[part 5 of 15: package /Cluster]
AUTOSAR XML (schema 4-3-0)
package /Cluster  (continued)
  can cluster HCP3_CANFD01: baudrate=500000, protocol-name=CAN, protocol-version=2.0, bus-off-recovery={bor-counter-l-1-to-l-2=1, bor-time-l-1=0.05, bor-time-l-2=0.2}, can-fd-baudrate=1000000  (continued)
    can physical channel CHNL: comm-connectors=CN_HCP3_CANFD01  (continued)
      frame PID_DispInpPID_Resp_FD_XIX_HCP3_CANFD01: id 0x1CD2236A, from HCP3_IONode, frame-length=64, can-addressing-mode=EXTENDED, can-frame-rx-behavior=CAN-FD, can-frame-tx-behavior=CAN-FD
        n pdu PID_DispInpPID_Resp_FD_XIX_HCP3_CANFD01: length=64
      frame PID_KeyInpPID_Req_FD_XIX_HCP3_CANFD01: id 0x1CD0236D, to HCP3_IONode, frame-length=64, can-addressing-mode=EXTENDED, can-frame-rx-behavior=CAN-FD, can-frame-tx-behavior=CAN-FD
        n pdu PID_KeyInpPID_Req_FD_XIX_HCP3_CANFD01: length=64
      frame PID_KeyInpPID_Resp_FD_XIX_HCP3_CANFD01: id 0x1CD2236D, from HCP3_IONode, frame-length=64, can-addressing-mode=EXTENDED, can-frame-rx-behavior=CAN-FD, can-frame-tx-behavior=CAN-FD
        n pdu PID_KeyInpPID_Resp_FD_XIX_HCP3_CANFD01: length=64
      frame PID_VA_Communication_Init_XIX_HCP3_CANFD01: id 0x16A95588, to HCP3_IONode, frame-length=20, can-addressing-mode=EXTENDED, can-frame-rx-behavior=CAN-FD, can-frame-tx-behavior=CAN-FD
        pdu PID_VA_Communication_Init_XIX_HCP3_CANFD01: length=20, minimum-delay=0.1, transmission-mode-true-timing={cyclic-timing={time-offset=0.0, time-period=1.0}, event-controlled-timing={number-of-repetitions=0, repetition-period=0.0}}, unused-bit-pattern=0
          signal PID_VA_Communication_Init_XIX_PID_VA_Communication_Init_XIX_HCP3_CANFD01: start 0, 136 bit, opaque, data-type-policy=OVERRIDE, i-signal-type=ARRAY, init-value=17 x 0, base-type=BT_PID_VA_Communication_Init, implementation-data-type=PID_VA_Communication_Init, transfer-property=TRIGGERED-ON-CHANGE-WITHOUT-REPETITION, to HCP3_IONode(timeout 5 s)  # This data channel is used for display video authentication of PID.
      frame PID_VA_Communication_Init_Ack_XIX_HCP3_CANFD01: id 0x16A9556A, to HCP3_IONode, frame-length=20, can-addressing-mode=EXTENDED, can-frame-rx-behavior=CAN-FD, can-frame-tx-behavior=CAN-FD
        pdu PID_VA_Communication_Init_Ack_XIX_HCP3_CANFD01: length=20, minimum-delay=0.1, transmission-mode-true-timing={cyclic-timing={time-offset=0.0, time-period=1.0}, event-controlled-timing={number-of-repetitions=0, repetition-period=0.0}}, unused-bit-pattern=0
          signal PID_VA_Communication_Init_Ack_XIX_PID_VA_Communication_Init_Ack_XIX_HCP3_CANFD01: start 0, 136 bit, opaque, data-type-policy=OVERRIDE, i-signal-type=ARRAY, init-value=17 x 0, base-type=BT_PID_VA_Communication_Init_Ack, implementation-data-type=PID_VA_Communication_Init_Ack, transfer-property=TRIGGERED-ON-CHANGE-WITHOUT-REPETITION, to HCP3_IONode(timeout 5 s)  # Init communication acknowledge of video-authentication for PID
      frame PID_VA_Response_XIX_HCP3_CANFD01: id 0x16A9556B, to HCP3_IONode, frame-length=64, can-addressing-mode=EXTENDED, can-frame-rx-behavior=CAN-FD, can-frame-tx-behavior=CAN-FD
        pdu PID_VA_Response_XIX_HCP3_CANFD01: length=64, minimum-delay=0.1, transmission-mode-true-timing={cyclic-timing={time-offset=0.0, time-period=1.0}, event-controlled-timing={number-of-repetitions=0, repetition-period=0.0}}, unused-bit-pattern=0
          signal PID_VA_Response_XIX_PID_VA_Response_XIX_HCP3_CANFD01: start 0, 512 bit, opaque, data-type-policy=OVERRIDE, i-signal-type=ARRAY, init-value=64 x 0, base-type=BT_PID_VA_Response, implementation-data-type=PID_VA_Response, transfer-property=TRIGGERED-ON-CHANGE-WITHOUT-REPETITION, to HCP3_IONode(timeout 5 s)  # Video-authentication response from PID
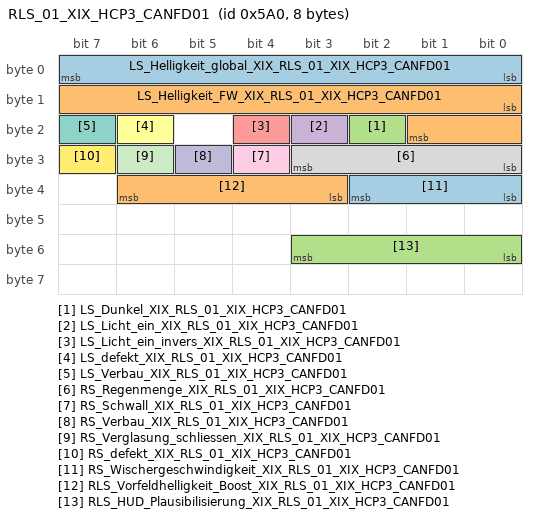
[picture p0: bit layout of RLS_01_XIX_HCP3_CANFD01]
      frame RLS_01_XIX_HCP3_CANFD01: id 0x5A0, from HCP3_IONode, frame-length=8, can-addressing-mode=STANDARD, can-frame-rx-behavior=CAN-FD, can-frame-tx-behavior=CAN-FD
        pdu RLS_01_XIX_HCP3_CANFD01: length=8, transmission-mode-true-timing=cyclic-timing={time-offset=0.0, time-period=0.2}, unused-bit-pattern=0  # 8Byte ab MLBevo LIN-CAN (1:1) Botschaften werden geroutet - wenn entsprechender Slave codiert ist - wenn fehlerfreie Kommunikation zum Slave besteht - bei fehlerhafter Kommunikation zum Slave wird die Botschaft für 4s mit den letzten gültigen Werten versendet
          signal LS_Helligkeit_global_XIX_RLS_01_XIX_HCP3_CANFD01: start 0, 8 bit, little-endian, data-type-policy=OVERRIDE, i-signal-type=PRIMITIVE, init-value=254, base-type=BT_LS_Helligkeit_global, invalid-value=Invalid_LS_Helligkeit_global_XIX_RLS_01_XIX_HCP3_CANFD01:255, compu {phys=raw*400 for raw 0..253, 255=Cxff_Fehler (CM_LS_Helligkeit_global_Cxff_Fehler), 254=Cxfe_Init (CM_LS_Helligkeit_global_Cxfe_Init); unit Unit_Lux}, range phys 0..101200 Unit_Lux, raw 0..255, unit=Unit_Lux, transfer-property=PENDING  # Globalfeldhelligkeit
          signal LS_Helligkeit_FW_XIX_RLS_01_XIX_HCP3_CANFD01: start 8, 10 bit, little-endian, data-type-policy=OVERRIDE, i-signal-type=PRIMITIVE, init-value=1022, base-type=BT_LS_Helligkeit_FW, invalid-value=Invalid_LS_Helligkeit_FW_XIX_RLS_01_XIX_HCP3_CANFD01:1023, compu {phys=raw*6 for raw 0..1021, 1023=Cx3ff_Fehler (CM_LS_Helligkeit_FW_Cx3ff_Fehler), 1022=Cx3fe_Init (CM_LS_Helligkeit_FW_Cx3fe_Init); unit Unit_Lux}, range phys 0..6126 Unit_Lux, raw 0..1023, unit=Unit_Lux, transfer-property=PENDING  # Vorfeldhelligkeit
          signal LS_Dunkel_XIX_RLS_01_XIX_HCP3_CANFD01: start 18, 1 bit, little-endian, data-type-policy=OVERRIDE, i-signal-type=PRIMITIVE, init-value=0, base-type=BT_LS_Dunkel, compu {1=Cx1_Dunkel (CM_LS_Dunkel_Cx1_Dunkel), 0=Cx0_Hell (CM_LS_Dunkel_Cx0_Hell)}, range raw 0..1, transfer-property=PENDING  # Regen- / Lichtsensor
          signal LS_Licht_ein_XIX_RLS_01_XIX_HCP3_CANFD01: start 19, 1 bit, little-endian, data-type-policy=OVERRIDE, i-signal-type=PRIMITIVE, init-value=0, base-type=BT_LS_Licht_ein, compu {1=Cx1_Ein (CM_LS_Licht_ein_Cx1_Ein), 0=Cx0_Aus (CM_LS_Licht_ein_Cx0_Aus)}, range raw 0..1, transfer-property=PENDING  # Anfoderung Fahrlicht
          signal LS_Licht_ein_invers_XIX_RLS_01_XIX_HCP3_CANFD01: start 20, 1 bit, little-endian, data-type-policy=OVERRIDE, i-signal-type=PRIMITIVE, init-value=1, base-type=BT_LS_Licht_ein_invers, compu {1=Cx1_Ein (CM_LS_Licht_ein_invers_Cx1_Ein), 0=Cx0_Aus (CM_LS_Licht_ein_invers_Cx0_Aus)}, range raw 0..1, transfer-property=PENDING  # Inversbit Anforderung Fahrlicht
          signal LS_defekt_XIX_RLS_01_XIX_HCP3_CANFD01: start 22, 1 bit, little-endian, data-type-policy=OVERRIDE, i-signal-type=PRIMITIVE, init-value=0, base-type=BT_LS_defekt, compu {0=Cx0_OK (CM_LS_defekt_Cx0_OK), 1=Cx1_defekt (CM_LS_defekt_Cx1_defekt)}, range raw 0..1, transfer-property=PENDING  # Fehlererkennung Lichtsensor
          signal LS_Verbau_XIX_RLS_01_XIX_HCP3_CANFD01: start 23, 1 bit, little-endian, data-type-policy=OVERRIDE, i-signal-type=PRIMITIVE, init-value=0, base-type=BT_LS_Verbau, compu {0=Cx0_Init (CM_LS_Verbau_Cx0_Init), 1=Cx1_Lichtsensor_verbaut (CM_LS_Verbau_Cx1_Lichtsensor_verbaut)}, range raw 0..1, transfer-property=PENDING  # Verbauinfo Lichtsensor
          signal RS_Regenmenge_XIX_RLS_01_XIX_HCP3_CANFD01: start 24, 4 bit, little-endian, data-type-policy=OVERRIDE, i-signal-type=PRIMITIVE, init-value=14, base-type=BT_RS_Regenmenge, invalid-value=Invalid_RS_Regenmenge_XIX_RLS_01_XIX_HCP3_CANFD01:15, compu {15=Cxf_Fehler (CM_RS_Regenmenge_Cxf_Fehler), 10=Cxa_9_01_bis_11_0 (CM_RS_Regenmenge_Cxa_9_01_bis_11_0) (9,01_bis_11,0), 5=Cx5_2_81_bis_3_3 (CM_RS_Regenmenge_Cx5_2_81_bis_3_3) (2,81_bis_3,3), 0=Cx0_0 (CM_RS_Regenmenge_Cx0_0), 9=Cx9_7_01_bis_9_0 (CM_RS_Regenmenge_Cx9_7_01_bis_9_0) (7,01_bis_9,0), 8=Cx8_5_01_bis_7_0 (CM_RS_Regenmenge_Cx8_5_01_bis_7_0) (5,01_bis_7,0), 14=Cxe_Init (CM_RS_Regenmenge_Cxe_Init), 4=Cx4_2_01_bis_2_8 (CM_RS_Regenmenge_Cx4_2_01_bis_2_8) (2,01_bis_2,8), 12=Cxc_15_01_bis_22_0 (CM_RS_Regenmenge_Cxc_15_01_bis_22_0) (15,01_bis_22,0), 3=Cx3_1_41_bis_2_0 (CM_RS_Regenmenge_Cx3_1_41_bis_2_0) (1,41_bis_2,0), 13=Cxd_22_01 (CM_RS_Regenmenge_Cxd_22_01) (>22,01), 11=Cxb_11_01_bis_15_0 (CM_RS_Regenmenge_Cxb_11_01_bis_15_0) (11,01_bis_15,0), 2=Cx2_0_31_bis_1_4 (CM_RS_Regenmenge_Cx2_0_31_bis_1_4) (0,31_bis_1,4), 7=Cx7_4_01_bis_5_0 (CM_RS_Regenmenge_Cx7_4_01_bis_5_0) (4,01_bis_5,0), 1=Cx1_0_0_bis_0_3 (CM_RS_Regenmenge_Cx1_0_0_bis_0_3) (0,0_bis_0,3), 6=Cx6_3_31_bis_4_0 (CM_RS_Regenmenge_Cx6_3_31_bis_4_0) (3,31_bis_4,0)}, range raw 0..15, transfer-property=PENDING  # Regenmenge
          signal RS_Schwall_XIX_RLS_01_XIX_HCP3_CANFD01: start 28, 1 bit, little-endian, data-type-policy=OVERRIDE, i-signal-type=PRIMITIVE, init-value=0, base-type=BT_RS_Schwall, compu {1=Cx1_Ein (CM_RS_Schwall_Cx1_Ein), 0=Cx0_Aus (CM_RS_Schwall_Cx0_Aus)}, range raw 0..1, transfer-property=PENDING  # Schwallereignis
          signal RS_Verbau_XIX_RLS_01_XIX_HCP3_CANFD01: start 29, 1 bit, little-endian, data-type-policy=OVERRIDE, i-signal-type=PRIMITIVE, init-value=0, base-type=BT_RS_Verbau, compu {1=Cx1_Regensensor_verbaut (CM_RS_Verbau_Cx1_Regensensor_verbaut) (Regensensor verbaut), 0=Cx0_Init (CM_RS_Verbau_Cx0_Init)}, range raw 0..1, transfer-property=PENDING  # Verbauinfo Regensensor
          signal RS_Verglasung_schliessen_XIX_RLS_01_XIX_HCP3_CANFD01: start 30, 1 bit, little-endian, data-type-policy=OVERRIDE, i-signal-type=PRIMITIVE, init-value=0, base-type=BT_RS_Verglasung_schliessen, compu {0=Cx0_Verglasung_nicht_schliessen (CM_RS_Verglasung_schliessen_Cx0_Verglasung_nicht_schliessen) (Verglasung nicht schliessen), 1=Cx1_Verglasung_schliessen (CM_RS_Verglasung_schliessen_Cx1_Verglasung_schliessen) (Verglasung schliessen)}, range raw 0..1, transfer-property=PENDING  # Anforderung: Verglasung schliessen
          signal RS_defekt_XIX_RLS_01_XIX_HCP3_CANFD01: start 31, 1 bit, little-endian, data-type-policy=OVERRIDE, i-signal-type=PRIMITIVE, init-value=0, base-type=BT_RS_defekt, compu {1=Cx1_defekt (CM_RS_defekt_Cx1_defekt), 0=Cx0_OK (CM_RS_defekt_Cx0_OK)}, range raw 0..1, transfer-property=PENDING  # Fehlererkennung Regensensor
          signal RS_Wischergeschwindigkeit_XIX_RLS_01_XIX_HCP3_CANFD01: start 32, 3 bit, little-endian, data-type-policy=OVERRIDE, i-signal-type=PRIMITIVE, init-value=0, base-type=BT_RS_Wischergeschwindigkeit, compu {4=Cx4_51_Huebe_min (CM_RS_Wischergeschwindigkeit_Cx4_51_Huebe_min) (51 Huebe/min), 0=Cx0_kein_Wischen (CM_RS_Wischergeschwindigkeit_Cx0_kein_Wischen) (kein Wischen), 2=Cx2_45_Huebe_min (CM_RS_Wischergeschwindigkeit_Cx2_45_Huebe_min) (45 Huebe/min), 1=Cx1_42_Huebe_min (CM_RS_Wischergeschwindigkeit_Cx1_42_Huebe_min) (42 Huebe/min), 3=Cx3_48_Huebe_min (CM_RS_Wischergeschwindigkeit_Cx3_48_Huebe_min) (48 Huebe/min), 6=Cx6_57_Huebe_min (CM_RS_Wischergeschwindigkeit_Cx6_57_Huebe_min) (57 Huebe/min), 7=Cx7_60_Huebe_min (CM_RS_Wischergeschwindigkeit_Cx7_60_Huebe_min) (60 Huebe/min), 5=Cx5_54_Huebe_min (CM_RS_Wischergeschwindigkeit_Cx5_54_Huebe_min) (54 Huebe/min)}, range raw 0..7, transfer-property=PENDING  # Wischergeschwindigkeit (Hübe/min)
          signal RLS_Vorfeldhelligkeit_Boost_XIX_RLS_01_XIX_HCP3_CANFD01: start 35, 4 bit, little-endian, data-type-policy=OVERRIDE, i-signal-type=PRIMITIVE, init-value=15, base-type=BT_RLS_Vorfeldhelligkeit_Boost, compu {9=Cx9_bis_11388_Lux (CM_RLS_Vorfeldhelligkeit_Boost_Cx9_bis_11388_Lux), 2=Cx2_bis_22193_Lux (CM_RLS_Vorfeldhelligkeit_Boost_Cx2_bis_22193_Lux), 0=Cx0_groesser_24413_Lux (CM_RLS_Vorfeldhelligkeit_Boost_Cx0_groesser_24413_Lux), 5=Cx5_bis_16647_Lux (CM_RLS_Vorfeldhelligkeit_Boost_Cx5_bis_16647_Lux), 4=Cx4_bis_18342_Lux (CM_RLS_Vorfeldhelligkeit_Boost_Cx4_bis_18342_Lux), 3=Cx3_bis_20176_Lux (CM_RLS_Vorfeldhelligkeit_Boost_Cx3_bis_20176_Lux), 6=Cx6_bis_15158_Lux (CM_RLS_Vorfeldhelligkeit_Boost_Cx6_bis_15158_Lux), 12=Cxc_bis_8556_Lux (CM_RLS_Vorfeldhelligkeit_Boost_Cxc_bis_8556_Lux), 11=Cxb_bis_9412_Lux (CM_RLS_Vorfeldhelligkeit_Boost_Cxb_bis_9412_Lux), 15=Cxf_bis_6428_Lux (CM_RLS_Vorfeldhelligkeit_Boost_Cxf_bis_6428_Lux), 14=Cxe_bis_7071_Lux (CM_RLS_Vorfeldhelligkeit_Boost_Cxe_bis_7071_Lux), 8=Cx8_bis_12527_Lux (CM_RLS_Vorfeldhelligkeit_Boost_Cx8_bis_12527_Lux), 7=Cx7_bis_13780_Lux (CM_RLS_Vorfeldhelligkeit_Boost_Cx7_bis_13780_Lux), 10=Cxa_bis_10353_Lux (CM_RLS_Vorfeldhelligkeit_Boost_Cxa_bis_10353_Lux), 1=Cx1_bis_24413_Lux (CM_RLS_Vorfeldhelligkeit_Boost_Cx1_bis_24413_Lux), 13=Cxd_bis_7778_Lux (CM_RLS_Vorfeldhelligkeit_Boost_Cxd_bis_7778_Lux)}, range raw 0..15, transfer-property=PENDING  # erweiterte Helligkeitssensierung für HUD
          signal RLS_HUD_Plausibilisierung_XIX_RLS_01_XIX_HCP3_CANFD01: start 48, 4 bit, little-endian, data-type-policy=OVERRIDE, i-signal-type=PRIMITIVE, init-value=0, base-type=BT_RLS_HUD_Plausibilisierung, compu {phys=raw for raw 0..15; unit Unit_None}, range phys 0..15 Unit_None, raw 0..15, unit=Unit_None, transfer-property=PENDING  # Plausibilisierung RLS -HUD
      frame RLSs_01_XIX_HCP3_CANFD01: id 0x27E, from HCP3_IONode, frame-length=8, can-addressing-mode=STANDARD, can-frame-rx-behavior=CAN-FD, can-frame-tx-behavior=CAN-FD
        pdu RLSs_01_XIX_HCP3_CANFD01: length=8, transmission-mode-true-timing=cyclic-timing={time-offset=0, time-period=0.06}, unused-bit-pattern=0
          signal RLS_BZ_XIX_RLSs_01_XIX_HCP3_CANFD01: start 0, 4 bit, little-endian, data-type-policy=OVERRIDE, i-signal-type=PRIMITIVE, base-type=BT_RLS_BZ, compu {phys=raw for raw 0..15}, range phys 0..15, raw 0..15, transfer-property=PENDING  # Botschaftszähler
          signal RLS_Qualifizierungsbit_XIX_RLSs_01_XIX_HCP3_CANFD01: start 4, 1 bit, little-endian, data-type-policy=OVERRIDE, i-signal-type=PRIMITIVE, init-value=0, base-type=BT_RLS_Qualifizierungsbit, compu {1=Cx1_gueltig (CM_RLS_Qualifizierungsbit_Cx1_gueltig), 0=Cx0_ungueltig (CM_RLS_Qualifizierungsbit_Cx0_ungueltig)}, range raw 0..1, transfer-property=PENDING  # Qualifizierungsbit für die Signale "LS_Licht_ein" und "LS_Licht_ein_invers"
          signal RS_Wischergeschwindigkeit_XIX_RLSs_01_XIX_HCP3_CANFD01: start 5, 3 bit, little-endian, data-type-policy=OVERRIDE, i-signal-type=PRIMITIVE, init-value=0, base-type=BT_RS_Wischergeschwindigkeit, compu {4=Cx4_51_Huebe_min (CM_RS_Wischergeschwindigkeit_Cx4_51_Huebe_min) (51 Huebe/min), 0=Cx0_kein_Wischen (CM_RS_Wischergeschwindigkeit_Cx0_kein_Wischen) (kein Wischen), 2=Cx2_45_Huebe_min (CM_RS_Wischergeschwindigkeit_Cx2_45_Huebe_min) (45 Huebe/min), 1=Cx1_42_Huebe_min (CM_RS_Wischergeschwindigkeit_Cx1_42_Huebe_min) (42 Huebe/min), 3=Cx3_48_Huebe_min (CM_RS_Wischergeschwindigkeit_Cx3_48_Huebe_min) (48 Huebe/min), 6=Cx6_57_Huebe_min (CM_RS_Wischergeschwindigkeit_Cx6_57_Huebe_min) (57 Huebe/min), 7=Cx7_60_Huebe_min (CM_RS_Wischergeschwindigkeit_Cx7_60_Huebe_min) (60 Huebe/min), 5=Cx5_54_Huebe_min (CM_RS_Wischergeschwindigkeit_Cx5_54_Huebe_min) (54 Huebe/min)}, range raw 0..7, transfer-property=PENDING  # Wischergeschwindigkeit (Hübe/min)
          signal RS_Schwall_XIX_RLSs_01_XIX_HCP3_CANFD01: start 8, 1 bit, little-endian, data-type-policy=OVERRIDE, i-signal-type=PRIMITIVE, init-value=0, base-type=BT_RS_Schwall, compu {1=Cx1_Ein (CM_RS_Schwall_Cx1_Ein), 0=Cx0_Aus (CM_RS_Schwall_Cx0_Aus)}, range raw 0..1, transfer-property=PENDING  # Schwallereignis
          signal RS_Verglasung_schliessen_XIX_RLSs_01_XIX_HCP3_CANFD01: start 9, 1 bit, little-endian, data-type-policy=OVERRIDE, i-signal-type=PRIMITIVE, init-value=0, base-type=BT_RS_Verglasung_schliessen, compu {0=Cx0_Verglasung_nicht_schliessen (CM_RS_Verglasung_schliessen_Cx0_Verglasung_nicht_schliessen) (Verglasung nicht schliessen), 1=Cx1_Verglasung_schliessen (CM_RS_Verglasung_schliessen_Cx1_Verglasung_schliessen) (Verglasung schliessen)}, range raw 0..1, transfer-property=PENDING  # Anforderung: Verglasung schliessen
          signal RS_versParklage_Wischer_XIX_RLSs_01_XIX_HCP3_CANFD01: start 10, 1 bit, little-endian, data-type-policy=OVERRIDE, i-signal-type=PRIMITIVE, init-value=0, base-type=BT_RS_versParklage_Wischer, compu {0=Cx0_Aus (CM_RS_versParklage_Wischer_Cx0_Aus), 1=Cx1_Ein (CM_RS_versParklage_Wischer_Cx1_Ein)}, range raw 0..1, transfer-property=PENDING  # versenkte Parklage Wischer
          signal LS_Licht_ein_XIX_RLSs_01_XIX_HCP3_CANFD01: start 11, 1 bit, little-endian, data-type-policy=OVERRIDE, i-signal-type=PRIMITIVE, init-value=0, base-type=BT_LS_Licht_ein, compu {1=Cx1_Ein (CM_LS_Licht_ein_Cx1_Ein), 0=Cx0_Aus (CM_LS_Licht_ein_Cx0_Aus)}, range raw 0..1, transfer-property=PENDING  # Anfoderung Fahrlicht
          signal LS_Licht_ein_invers_XIX_RLSs_01_XIX_HCP3_CANFD01: start 12, 1 bit, little-endian, data-type-policy=OVERRIDE, i-signal-type=PRIMITIVE, init-value=1, base-type=BT_LS_Licht_ein_invers, compu {1=Cx1_Ein (CM_LS_Licht_ein_invers_Cx1_Ein), 0=Cx0_Aus (CM_LS_Licht_ein_invers_Cx0_Aus)}, range raw 0..1, transfer-property=PENDING  # Inversbit Anforderung Fahrlicht
          signal LS_Dunkel_XIX_RLSs_01_XIX_HCP3_CANFD01: start 13, 1 bit, little-endian, data-type-policy=OVERRIDE, i-signal-type=PRIMITIVE, init-value=0, base-type=BT_LS_Dunkel, compu {1=Cx1_Dunkel (CM_LS_Dunkel_Cx1_Dunkel), 0=Cx0_Hell (CM_LS_Dunkel_Cx0_Hell)}, range raw 0..1, transfer-property=PENDING  # Regen- / Lichtsensor
          signal LS_Autobahnfahrlicht_XIX_RLSs_01_XIX_HCP3_CANFD01: start 14, 1 bit, little-endian, data-type-policy=OVERRIDE, i-signal-type=PRIMITIVE, init-value=0, base-type=BT_LS_Autobahnfahrlicht, compu {0=Cx0_Aus (CM_LS_Autobahnfahrlicht_Cx0_Aus), 1=Cx1_Ein (CM_LS_Autobahnfahrlicht_Cx1_Ein)}, range raw 0..1, transfer-property=PENDING  # Autobahnfahrlicht Anforderung
          signal RS_Regenfahrlicht_XIX_RLSs_01_XIX_HCP3_CANFD01: start 15, 1 bit, little-endian, data-type-policy=OVERRIDE, i-signal-type=PRIMITIVE, init-value=0, base-type=BT_RS_Regenfahrlicht, compu {1=Cx1_Ein (CM_RS_Regenfahrlicht_Cx1_Ein), 0=Cx0_Aus (CM_RS_Regenfahrlicht_Cx0_Aus)}, range raw 0..1, transfer-property=PENDING  # Regenlicht Anforderung
          signal RS_AdaptierungError_XIX_RLSs_01_XIX_HCP3_CANFD01: start 16, 1 bit, little-endian, data-type-policy=OVERRIDE, i-signal-type=PRIMITIVE, init-value=0, base-type=BT_RS_AdaptierungError, invalid-value=Invalid_RS_AdaptierungError_XIX_RLSs_01_XIX_HCP3_CANFD01:1, compu {1=Cx1_Fehler (CM_RS_AdaptierungError_Cx1_Fehler), 0=Cx0_normal (CM_RS_AdaptierungError_Cx0_normal)}, range raw 0..1, transfer-property=PENDING  # Adaptierungsfehler Regensensor
          signal RS_Error_XIX_RLSs_01_XIX_HCP3_CANFD01: start 17, 1 bit, little-endian, data-type-policy=OVERRIDE, i-signal-type=PRIMITIVE, init-value=0, base-type=BT_RS_Error, invalid-value=Invalid_RS_Error_XIX_RLSs_01_XIX_HCP3_CANFD01:1, compu {1=Cx1_Fehler (CM_RS_Error_Cx1_Fehler), 0=Cx0_normal (CM_RS_Error_Cx0_normal)}, range raw 0..1, transfer-property=PENDING  # Fehler/Defekt Regensensorik
          signal LS_Error_XIX_RLSs_01_XIX_HCP3_CANFD01: start 18, 1 bit, little-endian, data-type-policy=OVERRIDE, i-signal-type=PRIMITIVE, init-value=0, base-type=BT_LS_Error, invalid-value=Invalid_LS_Error_XIX_RLSs_01_XIX_HCP3_CANFD01:1, compu {1=Cx1_Fehler (CM_LS_Error_Cx1_Fehler), 0=Cx0_normal (CM_LS_Error_Cx0_normal)}, range raw 0..1, transfer-property=PENDING  # Fehler/Defekt Lichtsensorik
          signal RLS_ResponseError_XIX_RLSs_01_XIX_HCP3_CANFD01: start 19, 1 bit, little-endian, data-type-policy=OVERRIDE, i-signal-type=PRIMITIVE, init-value=0, base-type=BT_RLS_ResponseError, invalid-value=Invalid_RLS_ResponseError_XIX_RLSs_01_XIX_HCP3_CANFD01:1, compu {1=Cx1_Fehler (CM_RLS_ResponseError_Cx1_Fehler), 0=Cx0_normal (CM_RLS_ResponseError_Cx0_normal)}, range raw 0..1, transfer-property=PENDING  # siehe LIN2.0-Specification (Darf nicht über ein Fehlergueltigkeitsbit abgesichtert werden!)
          signal RLS_Vorfeldhelligkeit_Boost_XIX_RLSs_01_XIX_HCP3_CANFD01: start 20, 4 bit, little-endian, data-type-policy=OVERRIDE, i-signal-type=PRIMITIVE, init-value=15, base-type=BT_RLS_Vorfeldhelligkeit_Boost, compu {9=Cx9_bis_11388_Lux (CM_RLS_Vorfeldhelligkeit_Boost_Cx9_bis_11388_Lux), 2=Cx2_bis_22193_Lux (CM_RLS_Vorfeldhelligkeit_Boost_Cx2_bis_22193_Lux), 0=Cx0_groesser_24413_Lux (CM_RLS_Vorfeldhelligkeit_Boost_Cx0_groesser_24413_Lux), 5=Cx5_bis_16647_Lux (CM_RLS_Vorfeldhelligkeit_Boost_Cx5_bis_16647_Lux), 4=Cx4_bis_18342_Lux (CM_RLS_Vorfeldhelligkeit_Boost_Cx4_bis_18342_Lux), 3=Cx3_bis_20176_Lux (CM_RLS_Vorfeldhelligkeit_Boost_Cx3_bis_20176_Lux), 6=Cx6_bis_15158_Lux (CM_RLS_Vorfeldhelligkeit_Boost_Cx6_bis_15158_Lux), 12=Cxc_bis_8556_Lux (CM_RLS_Vorfeldhelligkeit_Boost_Cxc_bis_8556_Lux), 11=Cxb_bis_9412_Lux (CM_RLS_Vorfeldhelligkeit_Boost_Cxb_bis_9412_Lux), 15=Cxf_bis_6428_Lux (CM_RLS_Vorfeldhelligkeit_Boost_Cxf_bis_6428_Lux), 14=Cxe_bis_7071_Lux (CM_RLS_Vorfeldhelligkeit_Boost_Cxe_bis_7071_Lux), 8=Cx8_bis_12527_Lux (CM_RLS_Vorfeldhelligkeit_Boost_Cx8_bis_12527_Lux), 7=Cx7_bis_13780_Lux (CM_RLS_Vorfeldhelligkeit_Boost_Cx7_bis_13780_Lux), 10=Cxa_bis_10353_Lux (CM_RLS_Vorfeldhelligkeit_Boost_Cxa_bis_10353_Lux), 1=Cx1_bis_24413_Lux (CM_RLS_Vorfeldhelligkeit_Boost_Cx1_bis_24413_Lux), 13=Cxd_bis_7778_Lux (CM_RLS_Vorfeldhelligkeit_Boost_Cxd_bis_7778_Lux)}, range raw 0..15, transfer-property=PENDING  # erweiterte Helligkeitssensierung für HUD
          signal LS_Helligkeit_global_XIX_RLSs_01_XIX_HCP3_CANFD01: start 24, 8 bit, little-endian, data-type-policy=OVERRIDE, i-signal-type=PRIMITIVE, init-value=254, base-type=BT_LS_Helligkeit_global, invalid-value=Invalid_LS_Helligkeit_global_XIX_RLSs_01_XIX_HCP3_CANFD01:255, compu {phys=raw*400 for raw 0..253, 255=Cxff_Fehler (CM_LS_Helligkeit_global_Cxff_Fehler), 254=Cxfe_Init (CM_LS_Helligkeit_global_Cxfe_Init); unit Unit_Lux}, range phys 0..101200 Unit_Lux, raw 0..255, unit=Unit_Lux, transfer-property=PENDING  # Globalfeldhelligkeit
          signal LS_Helligkeit_FW_XIX_RLSs_01_XIX_HCP3_CANFD01: start 32, 10 bit, little-endian, data-type-policy=OVERRIDE, i-signal-type=PRIMITIVE, init-value=1022, base-type=BT_LS_Helligkeit_FW, invalid-value=Invalid_LS_Helligkeit_FW_XIX_RLSs_01_XIX_HCP3_CANFD01:1023, compu {phys=raw*6 for raw 0..1021, 1023=Cx3ff_Fehler (CM_LS_Helligkeit_FW_Cx3ff_Fehler), 1022=Cx3fe_Init (CM_LS_Helligkeit_FW_Cx3fe_Init); unit Unit_Lux}, range phys 0..6126 Unit_Lux, raw 0..1023, unit=Unit_Lux, transfer-property=PENDING  # Vorfeldhelligkeit
          signal RS_Regenmenge_XIX_RLSs_01_XIX_HCP3_CANFD01: start 44, 4 bit, little-endian, data-type-policy=OVERRIDE, i-signal-type=PRIMITIVE, init-value=14, base-type=BT_RS_Regenmenge, invalid-value=Invalid_RS_Regenmenge_XIX_RLSs_01_XIX_HCP3_CANFD01:15, compu {15=Cxf_Fehler (CM_RS_Regenmenge_Cxf_Fehler), 10=Cxa_9_01_bis_11_0 (CM_RS_Regenmenge_Cxa_9_01_bis_11_0) (9,01_bis_11,0), 5=Cx5_2_81_bis_3_3 (CM_RS_Regenmenge_Cx5_2_81_bis_3_3) (2,81_bis_3,3), 0=Cx0_0 (CM_RS_Regenmenge_Cx0_0), 9=Cx9_7_01_bis_9_0 (CM_RS_Regenmenge_Cx9_7_01_bis_9_0) (7,01_bis_9,0), 8=Cx8_5_01_bis_7_0 (CM_RS_Regenmenge_Cx8_5_01_bis_7_0) (5,01_bis_7,0), 14=Cxe_Init (CM_RS_Regenmenge_Cxe_Init), 4=Cx4_2_01_bis_2_8 (CM_RS_Regenmenge_Cx4_2_01_bis_2_8) (2,01_bis_2,8), 12=Cxc_15_01_bis_22_0 (CM_RS_Regenmenge_Cxc_15_01_bis_22_0) (15,01_bis_22,0), 3=Cx3_1_41_bis_2_0 (CM_RS_Regenmenge_Cx3_1_41_bis_2_0) (1,41_bis_2,0), 13=Cxd_22_01 (CM_RS_Regenmenge_Cxd_22_01) (>22,01), 11=Cxb_11_01_bis_15_0 (CM_RS_Regenmenge_Cxb_11_01_bis_15_0) (11,01_bis_15,0), 2=Cx2_0_31_bis_1_4 (CM_RS_Regenmenge_Cx2_0_31_bis_1_4) (0,31_bis_1,4), 7=Cx7_4_01_bis_5_0 (CM_RS_Regenmenge_Cx7_4_01_bis_5_0) (4,01_bis_5,0), 1=Cx1_0_0_bis_0_3 (CM_RS_Regenmenge_Cx1_0_0_bis_0_3) (0,0_bis_0,3), 6=Cx6_3_31_bis_4_0 (CM_RS_Regenmenge_Cx6_3_31_bis_4_0) (3,31_bis_4,0)}, range raw 0..15, transfer-property=PENDING  # Regenmenge
          signal RLSs_01_Checksum_XIX_RLSs_01_XIX_HCP3_CANFD01: start 56, 8 bit, little-endian, data-type-policy=OVERRIDE, i-signal-type=PRIMITIVE, init-value=0, base-type=BT_RLSs_01_Checksum, compu {phys=raw for raw 0..255; unit Unit_None}, range phys 0..255 Unit_None, raw 0..255, unit=Unit_None, transfer-property=PENDING  # Ab MQB und MLBevo: Berechnung siehe Lastenheft "End-to-End Kommunikationsabsicherung"
      frame RadioFunc_01_XIX_HCP3_CANFD01: id 0x16A9552B, from HCP3_IONode, frame-length=12, can-addressing-mode=EXTENDED, can-frame-rx-behavior=CAN-FD, can-frame-tx-behavior=CAN-FD
        pdu RadioFunc_01_XIX_HCP3_CANFD01: length=12, minimum-delay=0.05, transmission-mode-true-timing={cyclic-timing={time-offset=0.0, time-period=1.0}, event-controlled-timing={number-of-repetitions=0, repetition-period=0.0}}, unused-bit-pattern=0
          signal WLC1_Systemzustand_XIX_RadioFunc_01_XIX_HCP3_CANFD01: start 12, 1 bit, little-endian, data-type-policy=OVERRIDE, i-signal-type=PRIMITIVE, init-value=1, base-type=BT_WLC1_Systemzustand, compu {0=Cx0_Wireless_Charger_off (CM_WLC1_Systemzustand_Cx0_Wireless_Charger_off), 1=Cx1_InitWert_Wireless_Charger_on (CM_WLC1_Systemzustand_Cx1_InitWert_Wireless_Charger_on)}, range raw 0..1, transfer-property=PENDING  # 0 = Wireless Charger off (Message produced by HMI) 1 = Wireless Charger on (Message produced by HMI)
          signal WLC2_Systemzustand_XIX_RadioFunc_01_XIX_HCP3_CANFD01: start 13, 1 bit, little-endian, data-type-policy=OVERRIDE, i-signal-type=PRIMITIVE, init-value=1, base-type=BT_WLC2_Systemzustand, compu {0=Cx0_Wireless_Charger_off (CM_WLC2_Systemzustand_Cx0_Wireless_Charger_off), 1=Cx1_InitWert_Wireless_Charger_on (CM_WLC2_Systemzustand_Cx1_InitWert_Wireless_Charger_on)}, range raw 0..1, transfer-property=PENDING  # 0 = Wireless Charger off 1 = Wireless Charger on
          signal RA_Frequency_unit_XIX_RadioFunc_01_XIX_HCP3_CANFD01: start 14, 2 bit, little-endian, data-type-policy=OVERRIDE, i-signal-type=PRIMITIVE, init-value=0, base-type=BT_RA_Frequency_unit, compu {0=Cx0_1_kHz (CM_RA_Frequency_unit_Cx0_1_kHz), 1=Cx1_100_kHz (CM_RA_Frequency_unit_Cx1_100_kHz)}, range raw 0..1, transfer-property=TRIGGERED-ON-CHANGE-WITHOUT-REPETITION  # Faktor für RA_Frequency bei AM: Faktor 0 = 1kHz sonst Faktor 1 = 100kHz
          signal RA_Frequency_XIX_RadioFunc_01_XIX_HCP3_CANFD01: start 16, 14 bit, little-endian, data-type-policy=OVERRIDE, i-signal-type=PRIMITIVE, init-value=0, base-type=BT_RA_Frequency, compu {phys=raw for raw 0..16383; unit Unit_None}, range phys 0..16383 Unit_None, raw 0..16383, unit=Unit_None, transfer-property=TRIGGERED-ON-CHANGE-WITHOUT-REPETITION  # Übermittlung der eingestellten Sendefrequenz AM oder FM, diese wird mit RA_Frequency_unit multipliziert. Im DAB oder Hybrid/Online Mode wird die aktuelle FM-Alternativfrequenz oder, falls nicht vorhanden, die zuletzt gehörte Senderfrequenz übertragen (AM xor FM). Die CAN-Bus Signalempfänger verstimmen ihre Takt-/Oszillatorfrequenzen, so dass die eingestellte Radio-Sendefrequenz nicht gestört wird. Auf dem Bus werden nur statische Frequenzen übertragen.
          signal RA_AM_Tuning_XIX_RadioFunc_01_XIX_HCP3_CANFD01: start 30, 1 bit, little-endian, data-type-policy=OVERRIDE, i-signal-type=PRIMITIVE, init-value=0, base-type=BT_RA_AM_Tuning, compu {0=Cx0_frequency_locked (CM_RA_AM_Tuning_Cx0_frequency_locked), 1=Cx1_AM_tuning (CM_RA_AM_Tuning_Cx1_AM_tuning)}, range raw 0..1, transfer-property=TRIGGERED-ON-CHANGE-WITHOUT-REPETITION  # Das Signal kennzeichnet einen aktiven AM Suchlauf. Während des Suchlaufes wird die Frequenz = 0 übertragen. 0 = frequency locked => Störquelle vermeidet die aktuelle Frequenz 1 = AM tuning in progress => Störquelle abschalten bzw.PWM Signal auf DC umschalten
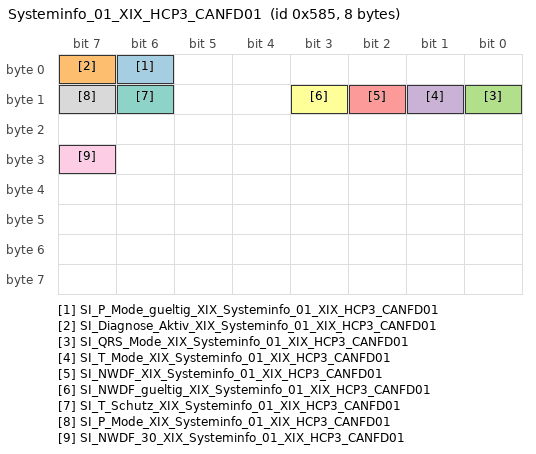
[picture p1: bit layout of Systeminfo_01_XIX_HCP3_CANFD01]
      frame Systeminfo_01_XIX_HCP3_CANFD01: id 0x585, from HCP3_IONode, frame-length=8, can-addressing-mode=STANDARD, can-frame-rx-behavior=CAN-FD, can-frame-tx-behavior=CAN-FD
        pdu Systeminfo_01_XIX_HCP3_CANFD01: length=8, minimum-delay=0.01, transmission-mode-true-timing={cyclic-timing={time-offset=0.0, time-period=1.0}, event-controlled-timing={number-of-repetitions=0, repetition-period=0.0}}, unused-bit-pattern=0  # MQB, MLBevo
          signal SI_P_Mode_gueltig_XIX_Systeminfo_01_XIX_HCP3_CANFD01: start 6, 1 bit, little-endian, data-type-policy=OVERRIDE, i-signal-type=PRIMITIVE, init-value=0, base-type=BT_SI_P_Mode_gueltig, compu {1=Cx1_zentraler_Produktionsmode (CM_SI_P_Mode_gueltig_Cx1_zentraler_Produktionsmode), 0=Cx0_dezentraler_Produktionsmode (CM_SI_P_Mode_gueltig_Cx0_dezentraler_Produktionsmode)}, range raw 0..1, transfer-property=PENDING  # zeigt an, ob es sich um ein Fahrzeug mit zentraler oder dezentraler Steu-erung des Produktionsmodes handelt Siehe Q-LAH Produktionsmode (LAH.DUM.907.AS)
          signal SI_Diagnose_Aktiv_XIX_Systeminfo_01_XIX_HCP3_CANFD01: start 7, 1 bit, little-endian, data-type-policy=OVERRIDE, i-signal-type=PRIMITIVE, init-value=0, base-type=BT_SI_Diagnose_Aktiv, compu {0=Cx0_inaktiv (CM_SI_Diagnose_Aktiv_Cx0_inaktiv), 1=Cx1_aktiv (CM_SI_Diagnose_Aktiv_Cx1_aktiv)}, range raw 0..1, transfer-property=PENDING  # Gibt an ob Diagnose-Botschaften empfangen werden und somit eine Diagnose aktiv ist. MQB: Gibt an ob Diagnose-Bus Botschaften empfangen werden und somit eine Diagnose aktiv ist.
          signal SI_QRS_Mode_XIX_Systeminfo_01_XIX_HCP3_CANFD01: start 8, 1 bit, little-endian, data-type-policy=OVERRIDE, i-signal-type=PRIMITIVE, init-value=0, base-type=BT_SI_QRS_Mode, compu {0=Cx0_QRS_Messmodus_nicht_aktiv (CM_SI_QRS_Mode_Cx0_QRS_Messmodus_nicht_aktiv), 1=Cx1_QRS_Messmodus_aktiv (CM_SI_QRS_Mode_Cx1_QRS_Messmodus_aktiv)}, range raw 0..1, transfer-property=PENDING  # Messmodus Quick-Ruhestrom
          signal SI_T_Mode_XIX_Systeminfo_01_XIX_HCP3_CANFD01: start 9, 1 bit, little-endian, data-type-policy=OVERRIDE, i-signal-type=PRIMITIVE, init-value=0, base-type=BT_SI_T_Mode, compu {0=Cx0_Transportmodus_nicht_aktiv (CM_SI_T_Mode_Cx0_Transportmodus_nicht_aktiv), 1=Cx1_Transportmodus_aktiv (CM_SI_T_Mode_Cx1_Transportmodus_aktiv)}, range raw 0..1, transfer-property=PENDING  # 0x0: Transportmodus nicht aktiv 0x1: Transportmodus aktiv
          signal SI_NWDF_XIX_Systeminfo_01_XIX_HCP3_CANFD01: start 10, 1 bit, little-endian, data-type-policy=OVERRIDE, i-signal-type=PRIMITIVE, init-value=0, base-type=BT_SI_NWDF, compu {1=Cx1_Ueberwachung_freigegeben (CM_SI_NWDF_Cx1_Ueberwachung_freigegeben), 0=Cx0_Ueberwachung_nicht_freigegeben (CM_SI_NWDF_Cx0_Ueberwachung_nicht_freigegeben)}, range raw 0..1, transfer-property=TRIGGERED-ON-CHANGE-WITHOUT-REPETITION  # Netzwerk-Diagnose Freigebe zur zentralen Aktivierung der Netzwerkdiagnose
          signal SI_NWDF_gueltig_XIX_Systeminfo_01_XIX_HCP3_CANFD01: start 11, 1 bit, little-endian, data-type-policy=OVERRIDE, i-signal-type=PRIMITIVE, init-value=1, base-type=BT_SI_NWDF_gueltig, compu {0=Cx0_NWDF_wird_nicht_unterstuetzt (CM_SI_NWDF_gueltig_Cx0_NWDF_wird_nicht_unterstuetzt), 1=Cx1_NWDF_wird_unterstuetzt (CM_SI_NWDF_gueltig_Cx1_NWDF_wird_unterstuetzt)}, range raw 0..1, transfer-property=PENDING  # Gültigkeitsbit zu SI_NWDF gemäß Lastenheft: Zentrale Aktivierung Netzwerkdiagnose
          signal SI_T_Schutz_XIX_Systeminfo_01_XIX_HCP3_CANFD01: start 14, 1 bit, little-endian, data-type-policy=OVERRIDE, i-signal-type=PRIMITIVE, init-value=0, base-type=BT_SI_T_Schutz, compu {0=Cx0_Transportschutz_nicht_aktiv (CM_SI_T_Schutz_Cx0_Transportschutz_nicht_aktiv), 1=Cx1_Transportschutz_aktiv (CM_SI_T_Schutz_Cx1_Transportschutz_aktiv)}, range raw 0..1, transfer-property=PENDING  # Transportschutz-Signal, das bei Transportmodus und Motorlauf aktiv bleibt 0x0: Transportschutz nicht aktiv 0x1: Transportschutz aktiv
          signal SI_P_Mode_XIX_Systeminfo_01_XIX_HCP3_CANFD01: start 15, 1 bit, little-endian, data-type-policy=OVERRIDE, i-signal-type=PRIMITIVE, init-value=0, base-type=BT_SI_P_Mode, compu {0=Cx0_inaktiv (CM_SI_P_Mode_Cx0_inaktiv), 1=Cx1_aktiv (CM_SI_P_Mode_Cx1_aktiv)}, range raw 0..1, transfer-property=PENDING  # Zentrale Steuerung des Produktionsmodes gemäß Q-LAH-Produktionsmode (LAH.DUM.907.AS)
          signal SI_NWDF_30_XIX_Systeminfo_01_XIX_HCP3_CANFD01: start 31, 1 bit, little-endian, data-type-policy=OVERRIDE, i-signal-type=PRIMITIVE, init-value=0, base-type=BT_SI_NWDF_30, compu {0=Cx0_Ueberwachung_nicht_freigegeben (CM_SI_NWDF_30_Cx0_Ueberwachung_nicht_freigegeben), 1=Cx1_Ueberwachung_freigegeben (CM_SI_NWDF_30_Cx1_Ueberwachung_freigegeben)}, range raw 0..1, transfer-property=TRIGGERED-ON-CHANGE-WITHOUT-REPETITION  # Netzwerk-Diagnose Freigabe zur zentralen Aktivierung der Netzwerkdiagnose (keine Ausblendbedingung aktiv)
      frame Systeminfo_02_XIX_HCP3_CANFD01: id 0x1A55549B, from HCP3_IONode, frame-length=12, can-addressing-mode=EXTENDED, can-frame-rx-behavior=CAN-FD, can-frame-tx-behavior=CAN-FD
        pdu Systeminfo_02_XIX_HCP3_CANFD01: length=12, minimum-delay=0.2, transmission-mode-true-timing={cyclic-timing={time-offset=0.0, time-period=1.0}, event-controlled-timing={number-of-repetitions=0, repetition-period=0.0}}, unused-bit-pattern=0
          signal SI_Bus_Identifikation_XIX_Systeminfo_02_XIX_HCP3_CANFD01: start 0, 8 bit, little-endian, data-type-policy=OVERRIDE, i-signal-type=PRIMITIVE, base-type=BT_SI_Bus_Identifikation, compu {33=Cx21_CAN_FahrerAssistenzSysteme (CM_SI_Bus_Identifikation_Cx21_CAN_FahrerAssistenzSysteme), 42=Cx2a_CAN_FahrerAssistenzSysteme_2 (CM_SI_Bus_Identifikation_Cx2a_CAN_FahrerAssistenzSysteme_2), 107=Cx6b_VLAN_Licht (CM_SI_Bus_Identifikation_Cx6b_VLAN_Licht), 23=Cx17_CAN_Lade (CM_SI_Bus_Identifikation_Cx17_CAN_Lade), 36=Cx24_CAN_AnzeigeBedienung (CM_SI_Bus_Identifikation_Cx24_CAN_AnzeigeBedienung), 199=Cxc7_WU_HCP2_CANFD (CM_SI_Bus_Identifikation_Cxc7_WU_HCP2_CANFD), 99=Cx63_VLAN_Connect (CM_SI_Bus_Identifikation_Cx63_VLAN_Connect), 98=Cx62_VLAN_Infotainment (CM_SI_Bus_Identifikation_Cx62_VLAN_Infotainment), 18=Cx12_CAN_Komfort (CM_SI_Bus_Identifikation_Cx12_CAN_Komfort), 106=Cx6a_VLAN_Connect_2 (CM_SI_Bus_Identifikation_Cx6a_VLAN_Connect_2), 49=Cx31_FlexRay_B (CM_SI_Bus_Identifikation_Cx31_FlexRay_B), 200=Cxc8_WU_HCP3_CANFD (CM_SI_Bus_Identifikation_Cxc8_WU_HCP3_CANFD), 101=Cx65_VLAN_Antrieb (CM_SI_Bus_Identifikation_Cx65_VLAN_Antrieb), 102=Cx66_VLAN_Diagnose (CM_SI_Bus_Identifikation_Cx66_VLAN_Diagnose), 179=Cxb3_HCP1_CANFD04 (CM_SI_Bus_Identifikation_Cxb3_HCP1_CANFD04), 195=Cxc3_ICAS1_CANFD2_HCP5_CANFD02 (CM_SI_Bus_Identifikation_Cxc3_ICAS1_CANFD2_HCP5_CANFD02), 34=Cx22_CAN_Migration (CM_SI_Bus_Identifikation_Cx22_CAN_Migration), 180=Cxb4_HCP1_CANFD05 (CM_SI_Bus_Identifikation_Cxb4_HCP1_CANFD05), 206=Cxce_HCP4_CANFD12 (CM_SI_Bus_Identifikation_Cxce_HCP4_CANFD12), 186=Cxba_HCP4_CANFD03 (CM_SI_Bus_Identifikation_Cxba_HCP4_CANFD03), 197=Cxc5_WU_HCP1_CANFD (CM_SI_Bus_Identifikation_Cxc5_WU_HCP1_CANFD), 182=Cxb6_HCP1_CANFD07 (CM_SI_Bus_Identifikation_Cxb6_HCP1_CANFD07), 108=Cx6c_VLAN_Charge (CM_SI_Bus_Identifikation_Cx6c_VLAN_Charge), 19=Cx13_CAN_Infotainment (CM_SI_Bus_Identifikation_Cx13_CAN_Infotainment), 201=Cxc9_WU_HCP4_CANFD (CM_SI_Bus_Identifikation_Cxc9_WU_HCP4_CANFD), 25=Cx19_CAN_Komfort_2 (CM_SI_Bus_Identifikation_Cx19_CAN_Komfort_2), 202=Cxca_HCP3_CANFD02 (CM_SI_Bus_Identifikation_Cxca_HCP3_CANFD02), 192=Cxc0_HCP4_CANFD09 (CM_SI_Bus_Identifikation_Cxc0_HCP4_CANFD09), 20=Cx14_CAN_Fahrwerk (CM_SI_Bus_Identifikation_Cx14_CAN_Fahrwerk), 26=Cx1a_CAN_AFS (CM_SI_Bus_Identifikation_Cx1a_CAN_AFS), 16=Cx10_CAN_Diagnose (CM_SI_Bus_Identifikation_Cx10_CAN_Diagnose), 183=Cxb7_HCP1_CANFD08 (CM_SI_Bus_Identifikation_Cxb7_HCP1_CANFD08), 181=Cxb5_HCP1_CANFD06 (CM_SI_Bus_Identifikation_Cxb5_HCP1_CANFD06), 47=Cx2f_CAN_Komfort_3 (CM_SI_Bus_Identifikation_Cx2f_CAN_Komfort_3), 194=Cxc2_HCP1_CANFD10 (CM_SI_Bus_Identifikation_Cxc2_HCP1_CANFD10), 204=Cxcc_ESC_CANFD (CM_SI_Bus_Identifikation_Cxcc_ESC_CANFD), 24=Cx18_CAN_Kombi (CM_SI_Bus_Identifikation_Cx18_CAN_Kombi), 187=Cxbb_HCP4_CANFD04 (CM_SI_Bus_Identifikation_Cxbb_HCP4_CANFD04), 109=Cx6d_VLAN_Cockpit (CM_SI_Bus_Identifikation_Cx6d_VLAN_Cockpit), 21=Cx15_CAN_Extended (CM_SI_Bus_Identifikation_Cx15_CAN_Extended), 22=Cx16_CAN_Hybrid (CM_SI_Bus_Identifikation_Cx16_CAN_Hybrid), 176=Cxb0_HCP1_CANFD01 (CM_SI_Bus_Identifikation_Cxb0_HCP1_CANFD01), 215=Cxd7_CAN_MobileDeviceKey (CM_SI_Bus_Identifikation_Cxd7_CAN_MobileDeviceKey), 193=Cxc1_HCP4_CANFD10 (CM_SI_Bus_Identifikation_Cxc1_HCP4_CANFD10), 41=Cx29_CAN_MFL (CM_SI_Bus_Identifikation_Cx29_CAN_MFL), 48=Cx30_FlexRay_A (CM_SI_Bus_Identifikation_Cx30_FlexRay_A), 205=Cxcd_HCP4_CANFD11 (CM_SI_Bus_Identifikation_Cxcd_HCP4_CANFD11), 27=Cx1b_CAN_MIB (CM_SI_Bus_Identifikation_Cx1b_CAN_MIB), 177=Cxb1_HCP1_CANFD02 (CM_SI_Bus_Identifikation_Cxb1_HCP1_CANFD02), 208=Cxd0_HCP5_CANFD05 (CM_SI_Bus_Identifikation_Cxd0_HCP5_CANFD05), 188=Cxbc_HCP1_CANFD09 (CM_SI_Bus_Identifikation_Cxbc_HCP1_CANFD09), 191=Cxbf_HCP4_CANFD08 (CM_SI_Bus_Identifikation_Cxbf_HCP4_CANFD08), 213=Cxd5_WU_PASD_CANFD (CM_SI_Bus_Identifikation_Cxd5_WU_PASD_CANFD), 103=Cx67_VLAN_Internet (CM_SI_Bus_Identifikation_Cx67_VLAN_Internet), 178=Cxb2_HCP1_CANFD03 (CM_SI_Bus_Identifikation_Cxb2_HCP1_CANFD03), 35=Cx23_CAN_Connect (CM_SI_Bus_Identifikation_Cx23_CAN_Connect), 40=Cx28_CAN_Telematik (CM_SI_Bus_Identifikation_Cx28_CAN_Telematik), 37=Cx25_CAN_ElectricalVehicle (CM_SI_Bus_Identifikation_Cx25_CAN_ElectricalVehicle), 196=Cxc4_HCP1_CANFD11 (CM_SI_Bus_Identifikation_Cxc4_HCP1_CANFD11), 189=Cxbd_HCP4_CANFD06 (CM_SI_Bus_Identifikation_Cxbd_HCP4_CANFD06), 97=Cx61_VLAN_FAS (CM_SI_Bus_Identifikation_Cx61_VLAN_FAS), 212=Cxd4_WU_ConMod_CANFD (CM_SI_Bus_Identifikation_Cxd4_WU_ConMod_CANFD), 207=Cxcf_HCP5_CANFD04 (CM_SI_Bus_Identifikation_Cxcf_HCP5_CANFD04), 104=Cx68_VLAN_Gateway (CM_SI_Bus_Identifikation_Cx68_VLAN_Gateway), 190=Cxbe_HCP4_CANFD07 (CM_SI_Bus_Identifikation_Cxbe_HCP4_CANFD07), 105=Cx69_VLAN_Remote_FC (CM_SI_Bus_Identifikation_Cx69_VLAN_Remote_FC), 17=Cx11_CAN_Antrieb (CM_SI_Bus_Identifikation_Cx11_CAN_Antrieb), 100=Cx64_VLAN_Komfort (CM_SI_Bus_Identifikation_Cx64_VLAN_Komfort)}, range raw 16..215, transfer-property=PENDING  # Das Signal identifiziert den Bus eindeutig. Das Signal ist konstant auf jedem Bus. Der Signalwert entspricht dem Wert "Busnummer" aus der VW80127 Gateway_component_list_databus_identification (0x2A2D) "Bus-Identifier".
          signal SI_FCAB_XIX_Systeminfo_02_XIX_HCP3_CANFD01: start 16, 56 bit, opaque, data-type-policy=OVERRIDE, i-signal-type=ARRAY, init-value=7 x 0b00000000, base-type=BT_SI_FCAB, compu {phys=raw for raw 0..72057594037927935, 8796093022208=Cx80000000000_44_Diagnosis_Infotainment (CM_SI_FCAB_Cx80000000000_44_Diagnosis_Infotainment), 70368744177664=Cx400000000000_47_Diagnosis_ComfortLins (CM_SI_FCAB_Cx400000000000_47_Diagnosis_ComfortLins), 34359738368=Cx800000000_36_Preheater (CM_SI_FCAB_Cx800000000_36_Preheater), 68719476736=Cx1000000000_37_Highvoltage_WirelessChargingStation (CM_SI_FCAB_Cx1000000000_37_Highvoltage_WirelessChargingStation), 549755813888=Cx8000000000_40_Diagnosis_Energy (CM_SI_FCAB_Cx8000000000_40_Diagnosis_Energy), 1099511627776=Cx10000000000_41_Diagnosis_Powertrain (CM_SI_FCAB_Cx10000000000_41_Diagnosis_Powertrain), 2199023255552=Cx20000000000_42_Diagnosis_FlexRay (CM_SI_FCAB_Cx20000000000_42_Diagnosis_FlexRay), 0=Cx0_Init (CM_SI_FCAB_Cx0_Init), 8=Cx8_04_Basefunction_DrivingAssistance (CM_SI_FCAB_Cx8_04_Basefunction_DrivingAssistance), 128=Cx80_08_Basefunction_Connectivity (CM_SI_FCAB_Cx80_08_Basefunction_Connectivity), 16384=Cx4000_15_InstrumentclusterDisplay (CM_SI_FCAB_Cx4000_15_InstrumentclusterDisplay), 2048=Cx800_12_GearSelector (CM_SI_FCAB_Cx800_12_GearSelector), 4=Cx4_03_Basefunction_Chassis (CM_SI_FCAB_Cx4_03_Basefunction_Chassis), 2=Cx2_02_Basefunction_Powertrain (CM_SI_FCAB_Cx2_02_Basefunction_Powertrain), 256=Cx100_09_reserved (CM_SI_FCAB_Cx100_09_reserved) (09_<reserved>), 4096=Cx1000_13_Airbag (CM_SI_FCAB_Cx1000_13_Airbag), 512=Cx200_10_Powertrain (CM_SI_FCAB_Cx200_10_Powertrain), 32=Cx20_06_Basefunction_ComfortLight (CM_SI_FCAB_Cx20_06_Basefunction_ComfortLight), 8192=Cx2000_14_InfotainmentExtensions (CM_SI_FCAB_Cx2000_14_InfotainmentExtensions), 64=Cx40_07_Basefunction_CrossSection (CM_SI_FCAB_Cx40_07_Basefunction_CrossSection), 1=Cx1_01_CarWakeUp (CM_SI_FCAB_Cx1_01_CarWakeUp), 16=Cx10_05_Basefunction_Infotainment (CM_SI_FCAB_Cx10_05_Basefunction_Infotainment), 32768=Cx8000_16_InfotainmentDisplay (CM_SI_FCAB_Cx8000_16_InfotainmentDisplay), 1024=Cx400_11_Chassis (CM_SI_FCAB_Cx400_11_Chassis), 65536=Cx10000_17_Audio (CM_SI_FCAB_Cx10000_17_Audio), 131072=Cx20000_18_VirtualSideMirrors (CM_SI_FCAB_Cx20000_18_VirtualSideMirrors), 262144=Cx40000_19_Doors_Hatches (CM_SI_FCAB_Cx40000_19_Doors_Hatches), 524288=Cx80000_20_OptionalComfort (CM_SI_FCAB_Cx80000_20_OptionalComfort), 1048576=Cx100000_21_AirSuspension (CM_SI_FCAB_Cx100000_21_AirSuspension), 4194304=Cx400000_23_Climate (CM_SI_FCAB_Cx400000_23_Climate), 8388608=Cx800000_24_ThermoManagement (CM_SI_FCAB_Cx800000_24_ThermoManagement), 2097152=Cx200000_22_ExteriorLights (CM_SI_FCAB_Cx200000_22_ExteriorLights), 16777216=Cx1000000_25_AccessSystemSensors (CM_SI_FCAB_Cx1000000_25_AccessSystemSensors), 33554432=Cx2000000_26_HighVoltage_Charging (CM_SI_FCAB_Cx2000000_26_HighVoltage_Charging), 134217728=Cx8000000_28_OnboardTester_DataCollector (CM_SI_FCAB_Cx8000000_28_OnboardTester_DataCollector), 67108864=Cx4000000_27_Timemaster_Timer (CM_SI_FCAB_Cx4000000_27_Timemaster_Timer), 268435456=Cx10000000_29_SteeringColumnLock (CM_SI_FCAB_Cx10000000_29_SteeringColumnLock), 536870912=Cx20000000_30_EnergyManagement (CM_SI_FCAB_Cx20000000_30_EnergyManagement), 1073741824=Cx40000000_31_MultifunctionalSteeringWheel (CM_SI_FCAB_Cx40000000_31_MultifunctionalSteeringWheel), 2147483648=Cx80000000_32_OnlineAccess (CM_SI_FCAB_Cx80000000_32_OnlineAccess), 4294967296=Cx100000000_33_ExternalWirelessCommunication (CM_SI_FCAB_Cx100000000_33_ExternalWirelessCommunication), 8589934592=Cx200000000_34_GPS_Localization (CM_SI_FCAB_Cx200000000_34_GPS_Localization), 17179869184=Cx400000000_35_ExteriorSound (CM_SI_FCAB_Cx400000000_35_ExteriorSound), 4398046511104=Cx40000000000_43_Diagnosis_DrivingAssistance (CM_SI_FCAB_Cx40000000000_43_Diagnosis_DrivingAssistance), 17592186044416=Cx100000000000_45_Diagnosis_Comfort (CM_SI_FCAB_Cx100000000000_45_Diagnosis_Comfort), 35184372088832=Cx200000000000_46_Diagnosis_Light (CM_SI_FCAB_Cx200000000000_46_Diagnosis_Light), 140737488355328=Cx800000000000_48_Diagnosis_ClimateTmeLINs (CM_SI_FCAB_Cx800000000000_48_Diagnosis_ClimateTmeLINs), 281474976710656=Cx1000000000000_49_reserved (CM_SI_FCAB_Cx1000000000000_49_reserved) (49_<reserved>), 4503599627370490=Cxffffffffffffa_53_Lock_Unlock (CM_SI_FCAB_Cxffffffffffffa_53_Lock_Unlock), 9007199254740990=Cx1ffffffffffffe_54_reserved (CM_SI_FCAB_Cx1ffffffffffffe_54_reserved) (54_<reserved>), 18014398509481900=Cx3fffffffffffac_55_Dimming (CM_SI_FCAB_Cx3fffffffffffac_55_Dimming), 36028797018963900=Cx7fffffffffffbc_56_ChargingStatus (CM_SI_FCAB_Cx7fffffffffffbc_56_ChargingStatus)}, range phys 0..72057594037927935, raw 0..72057594037927935, transfer-property=TRIGGERED-ON-CHANGE-WITHOUT-REPETITION  # FCAB = Funktions-Cluster-Aktiv-Bits
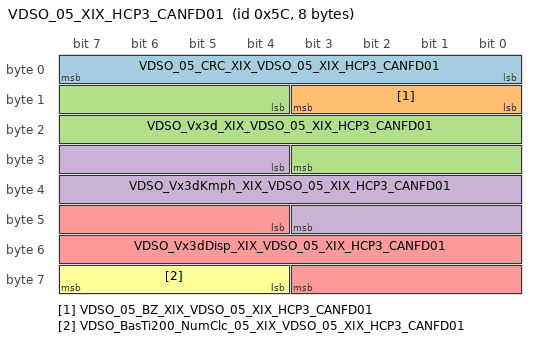
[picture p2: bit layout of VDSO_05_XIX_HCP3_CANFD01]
      frame VDSO_05_XIX_HCP3_CANFD01: id 0x5C, from HCP3_IONode, frame-length=8, can-addressing-mode=STANDARD, can-frame-rx-behavior=CAN-FD, can-frame-tx-behavior=CAN-FD
        pdu VDSO_05_XIX_HCP3_CANFD01: length=8, transmission-mode-true-timing=cyclic-timing={time-offset=0.0, time-period=0.005}, unused-bit-pattern=0
          signal VDSO_05_CRC_XIX_VDSO_05_XIX_HCP3_CANFD01: start 0, 8 bit, little-endian, data-type-policy=OVERRIDE, i-signal-type=PRIMITIVE, init-value=0, base-type=BT_VDSO_05_CRC, compu {phys=raw for raw 0..255}, range phys 0..255, raw 0..255  # Für MLB: Berechnung siehe Lastenheft "Kommunikationsabsicherung für FlexRay und CAN" Ab MQB und MLBevo: Berechnung siehe Lastenheft "End-to-End Kommunikationsabsicherung" Endwerte siehe Begleitdokument "S-PDU Kennungsfolgen"
          signal VDSO_05_BZ_XIX_VDSO_05_XIX_HCP3_CANFD01: start 8, 4 bit, little-endian, data-type-policy=OVERRIDE, i-signal-type=PRIMITIVE, init-value=0, base-type=BT_VDSO_05_BZ, compu {phys=raw for raw 0..15}, range phys 0..15, raw 0..15  # 4bit Botschaftszähler, wird mit jeder Sendebotschaft inkrementiert
          signal VDSO_Vx3d_XIX_VDSO_05_XIX_HCP3_CANFD01: start 12, 16 bit, little-endian, data-type-policy=OVERRIDE, i-signal-type=PRIMITIVE, init-value=65534, base-type=BT_VDSO_Vx3d, invalid-value=Invalid_VDSO_Vx3d_XIX_VDSO_05_XIX_HCP3_CANFD01:65535, compu {phys=raw*0.0039-127.7874 for raw 0..65533, 65535=Cxffff_Fehler (CM_VDSO_Vx3d_Cxffff_Fehler), 65534=Cxfffe_Init (CM_VDSO_Vx3d_Cxfffe_Init); unit Unit_MeterPerSecon}, range phys -127.7874..127.7913 Unit_MeterPerSecon, raw 0..65535, unit=Unit_MeterPerSecon  # Geschwindigkeitssignal vom ABS/ASR oder ESP. Mittelwert der angetriebenen Räder. Bei MSR oder ABS Eingriffen wird die ABS-Referenzgeschwindigkeit für >= 200ms eingespiegelt (Zeit wird mit Aktiv-Flanke der Funktionsbits getriggert) MQB: Bei Frontantrieb und gesteuertem Allrad (Haldex) Mittelwert der Vorderräder.
          signal VDSO_Vx3dKmph_XIX_VDSO_05_XIX_HCP3_CANFD01: start 28, 16 bit, little-endian, data-type-policy=OVERRIDE, i-signal-type=PRIMITIVE, init-value=65534, base-type=BT_VDSO_Vx3dKmph, invalid-value=Invalid_VDSO_Vx3dKmph_XIX_VDSO_05_XIX_HCP3_CANFD01:65535, compu {phys=raw*0.014-458.724 for raw 0..65533, 65535=Cxffff_Fehler (CM_VDSO_Vx3dKmph_Cxffff_Fehler), 65534=Cxfffe_Init (CM_VDSO_Vx3dKmph_Cxfffe_Init); unit Unit_KiloMeterPerHour}, range phys -458.724..458.738 Unit_KiloMeterPerHour, raw 0..65535, unit=Unit_KiloMeterPerHour  # Longitudinal velocity estimated at the centre of rear axle. Estimation requires 3D IMU.
          signal VDSO_Vx3dDisp_XIX_VDSO_05_XIX_HCP3_CANFD01: start 44, 16 bit, little-endian, data-type-policy=OVERRIDE, i-signal-type=PRIMITIVE, init-value=65534, base-type=BT_VDSO_Vx3dDisp, invalid-value=Invalid_VDSO_Vx3dDisp_XIX_VDSO_05_XIX_HCP3_CANFD01:65535, compu {phys=raw*0.0039-127.7874 for raw 0..65533, 65535=Cxffff_Fehler (CM_VDSO_Vx3dDisp_Cxffff_Fehler), 65534=Cxfffe_Init (CM_VDSO_Vx3dDisp_Cxfffe_Init); unit Unit_MeterPerSecon}, range phys -127.7874..127.7913 Unit_MeterPerSecon, raw 0..65535, unit=Unit_MeterPerSecon  # VDSO_Vx3d incl. additional scaling to meet official regulations (Typ approval. NCAP eg)
          signal VDSO_BasTi200_NumClc_05_XIX_VDSO_05_XIX_HCP3_CANFD01: start 60, 4 bit, little-endian, data-type-policy=OVERRIDE, i-signal-type=PRIMITIVE, base-type=BT_VDSO_BasTi200_NumClc_05, compu {phys=raw for raw 0..15; unit Unit_None}, range phys 0..15 Unit_None, raw 0..15, unit=Unit_None  # CalculationNumber of the VDSO 200 Runnable to enable PDU-TLT merge in receiver ECU
          mapping SG_VDSO_05_XIX_HCP3_CANFD01: i-signal-group=SG_VDSO_05_XIX_HCP3_CANFD01, transfer-property=TRIGGERED-WITHOUT-REPETITION
      frame VDSO_09_XIX_HCP3_CANFD01: id 0x2F95404, from HCP3_IONode, frame-length=32, can-addressing-mode=EXTENDED, can-frame-rx-behavior=CAN-FD, can-frame-tx-behavior=CAN-FD
        pdu VDSO_09_XIX_HCP3_CANFD01: length=32, transmission-mode-true-timing=cyclic-timing={time-offset=0.0, time-period=0.005}, unused-bit-pattern=0
          signal VDSO_09_CRC_XIX_VDSO_09_XIX_HCP3_CANFD01: start 0, 8 bit, little-endian, data-type-policy=OVERRIDE, i-signal-type=PRIMITIVE, init-value=0, base-type=BT_VDSO_09_CRC, compu {phys=raw for raw 0..255}, range phys 0..255, raw 0..255, transfer-property=TRIGGERED-WITHOUT-REPETITION  # Für MLB: Berechnung siehe Lastenheft "Kommunikationsabsicherung für FlexRay und CAN" Ab MQB und MLBevo: Berechnung siehe Lastenheft "End-to-End Kommunikationsabsicherung" Endwerte siehe Begleitdokument "S-PDU Kennungsfolgen"
          signal VDSO_09_BZ_XIX_VDSO_09_XIX_HCP3_CANFD01: start 8, 4 bit, little-endian, data-type-policy=OVERRIDE, i-signal-type=PRIMITIVE, init-value=0, base-type=BT_VDSO_09_BZ, compu {phys=raw for raw 0..15}, range phys 0..15, raw 0..15, transfer-property=TRIGGERED-WITHOUT-REPETITION  # 4bit Botschaftszähler, wird mit jeder Sendebotschaft inkrementiert
          signal VDSO_AgFrWhlStgAxlOfsCmp_XIX_VDSO_09_XIX_HCP3_CANFD01: start 12, 16 bit, little-endian, data-type-policy=OVERRIDE, i-signal-type=PRIMITIVE, init-value=65534, base-type=BT_VDSO_AgFrWhlStgAxlOfsCmp, invalid-value=Invalid_VDSO_AgFrWhlStgAxlOfsCmp_XIX_VDSO_09_XIX_HCP3_CANFD01:65535, compu {phys=raw*3.195890839e-05-1.047197551 for raw 0..65533, 65535=Cxffff_Fehler (CM_VDSO_AgFrWhlStgAxlOfsCmp_Cxffff_Fehler), 65534=Cxfffe_Init (CM_VDSO_AgFrWhlStgAxlOfsCmp_Cxfffe_Init); unit Unit_Radia}, range phys -1.0471975511966..1.0471655922882046 Unit_Radia, raw 0..65535, unit=Unit_Radia, transfer-property=TRIGGERED-WITHOUT-REPETITION  # Steering angle of front axle including EPS-Straight-Forward-Correction. Calculation based on EPS-Signals. For ASIL requirements VDSO_StAgFrWhlStgAxl has to be monitored.
          signal VDSO_ALatOfs_XIX_VDSO_09_XIX_HCP3_CANFD01: start 28, 10 bit, little-endian, data-type-policy=OVERRIDE, i-signal-type=PRIMITIVE, init-value=1022, base-type=BT_VDSO_ALatOfs, invalid-value=Invalid_VDSO_ALatOfs_XIX_VDSO_09_XIX_HCP3_CANFD01:1023, compu {phys=raw*0.005-2.5 for raw 0..1021, 1023=Cx3ff_Fehler (CM_VDSO_ALatOfs_Cx3ff_Fehler), 1022=Cx3fe_Init (CM_VDSO_ALatOfs_Cx3fe_Init); unit Unit_MeterPerSeconSquar}, range phys -2.5..2.605 Unit_MeterPerSeconSquar, raw 0..1023, unit=Unit_MeterPerSeconSquar, transfer-property=TRIGGERED-WITHOUT-REPETITION  # Static offset of lateral acceleration sensor. Formula: Sensor Value - Offset = True Value
          signal VDSO_ALgtOfs_XIX_VDSO_09_XIX_HCP3_CANFD01: start 38, 10 bit, little-endian, data-type-policy=OVERRIDE, i-signal-type=PRIMITIVE, init-value=1022, base-type=BT_VDSO_ALgtOfs, invalid-value=Invalid_VDSO_ALgtOfs_XIX_VDSO_09_XIX_HCP3_CANFD01:1023, compu {phys=raw*0.005-2.5 for raw 0..1021, 1023=Cx3ff_Fehler (CM_VDSO_ALgtOfs_Cx3ff_Fehler), 1022=Cx3fe_Init (CM_VDSO_ALgtOfs_Cx3fe_Init); unit Unit_MeterPerSeconSquar}, range phys -2.5..2.605 Unit_MeterPerSeconSquar, raw 0..1023, unit=Unit_MeterPerSeconSquar, transfer-property=TRIGGERED-WITHOUT-REPETITION  # Static offset of longitudinal acceleration sensor. Formula: Sensor Value - Offset = True Value
          signal VDSO_StVx3d_XIX_VDSO_09_XIX_HCP3_CANFD01: start 48, 4 bit, little-endian, data-type-policy=OVERRIDE, i-signal-type=PRIMITIVE, init-value=0, base-type=BT_VDSO_StVx3d, compu {7=Cx7_degradation_7 (CM_VDSO_StVx3d_Cx7_degradation_7), 2=Cx2_degradation_2 (CM_VDSO_StVx3d_Cx2_degradation_2), 8=Cx8_degradation_8 (CM_VDSO_StVx3d_Cx8_degradation_8), 3=Cx3_degradation_3 (CM_VDSO_StVx3d_Cx3_degradation_3), 0=Cx0_no_degradation (CM_VDSO_StVx3d_Cx0_no_degradation), 1=Cx1_degradation_1 (CM_VDSO_StVx3d_Cx1_degradation_1), 5=Cx5_degradation_5 (CM_VDSO_StVx3d_Cx5_degradation_5), 4=Cx4_degradation_4 (CM_VDSO_StVx3d_Cx4_degradation_4), 6=Cx6_degradation_6 (CM_VDSO_StVx3d_Cx6_degradation_6)}, range raw 0..8, transfer-property=TRIGGERED-WITHOUT-REPETITION  # Signal describes the estimation mode of Vx3d state estimation. If sensors which are required for normal Vx3d estimation are not recieved valid (e.g. broken sensor / bus) or can't be provided (e.g. GPS during tunnel) Vx3d will switch to the next best estimation algorithm. Reduced accuracy is to be expected with increased degradation.
          signal VDSO_AgReWhlStgAxl_XIX_VDSO_09_XIX_HCP3_CANFD01: start 52, 14 bit, little-endian, data-type-policy=OVERRIDE, i-signal-type=PRIMITIVE, init-value=16382, base-type=BT_VDSO_AgReWhlStgAxl, invalid-value=Invalid_VDSO_AgReWhlStgAxl_XIX_VDSO_09_XIX_HCP3_CANFD01:16383, compu {phys=raw*3.195890839e-05-0.2617993878 for raw 0..16381, 16383=Cx3fff_Fehler (CM_VDSO_AgReWhlStgAxl_Cx3fff_Fehler), 16382=Cx3ffe_Init (CM_VDSO_AgReWhlStgAxl_Cx3ffe_Init); unit Unit_Radia}, range phys -0.261799387799149..0.2617194905281762 Unit_Radia, raw 0..16383, unit=Unit_Radia, transfer-property=TRIGGERED-WITHOUT-REPETITION  # Steering angle of rear axle.
          signal VDSO_WhlSlipFrLe3d_XIX_VDSO_09_XIX_HCP3_CANFD01: start 66, 8 bit, little-endian, data-type-policy=OVERRIDE, i-signal-type=PRIMITIVE, init-value=254, base-type=BT_VDSO_WhlSlipFrLe3d, invalid-value=Invalid_VDSO_WhlSlipFrLe3d_XIX_VDSO_09_XIX_HCP3_CANFD01:255, compu {phys=raw/126-1 for raw 0..252, 255=Cxff_Fehler (CM_VDSO_WhlSlipFrLe3d_Cxff_Fehler), 254=Cxfe_Init (CM_VDSO_WhlSlipFrLe3d_Cxfe_Init); unit Unit_None}, range phys -1..1.0000000000000009 Unit_None, raw 0..255, unit=Unit_None, transfer-property=TRIGGERED-WITHOUT-REPETITION  # Estimated wheel slip front left. Estimation requires 3D IMU
          signal VDSO_WhlSlipFrRi3d_XIX_VDSO_09_XIX_HCP3_CANFD01: start 74, 8 bit, little-endian, data-type-policy=OVERRIDE, i-signal-type=PRIMITIVE, init-value=254, base-type=BT_VDSO_WhlSlipFrRi3d, invalid-value=Invalid_VDSO_WhlSlipFrRi3d_XIX_VDSO_09_XIX_HCP3_CANFD01:255, compu {phys=raw/126-1 for raw 0..252, 255=Cxff_Fehler (CM_VDSO_WhlSlipFrRi3d_Cxff_Fehler), 254=Cxfe_Init (CM_VDSO_WhlSlipFrRi3d_Cxfe_Init); unit Unit_None}, range phys -1..1.0000000000000009 Unit_None, raw 0..255, unit=Unit_None, transfer-property=TRIGGERED-WITHOUT-REPETITION  # Estimated wheel slip front right. Estimation requires 3D IMU
          signal VDSO_WhlSlipReLe3d_XIX_VDSO_09_XIX_HCP3_CANFD01: start 82, 8 bit, little-endian, data-type-policy=OVERRIDE, i-signal-type=PRIMITIVE, init-value=254, base-type=BT_VDSO_WhlSlipReLe3d, invalid-value=Invalid_VDSO_WhlSlipReLe3d_XIX_VDSO_09_XIX_HCP3_CANFD01:255, compu {phys=raw/126-1 for raw 0..252, 255=Cxff_Fehler (CM_VDSO_WhlSlipReLe3d_Cxff_Fehler), 254=Cxfe_Init (CM_VDSO_WhlSlipReLe3d_Cxfe_Init); unit Unit_None}, range phys -1..1.0000000000000009 Unit_None, raw 0..255, unit=Unit_None, transfer-property=TRIGGERED-WITHOUT-REPETITION  # Estimated wheel slip rear left. Estimation requires 3D IMU
          signal VDSO_WhlSlipReRi3d_XIX_VDSO_09_XIX_HCP3_CANFD01: start 90, 8 bit, little-endian, data-type-policy=OVERRIDE, i-signal-type=PRIMITIVE, init-value=254, base-type=BT_VDSO_WhlSlipReRi3d, invalid-value=Invalid_VDSO_WhlSlipReRi3d_XIX_VDSO_09_XIX_HCP3_CANFD01:255, compu {phys=raw/126-1 for raw 0..252, 255=Cxff_Fehler (CM_VDSO_WhlSlipReRi3d_Cxff_Fehler), 254=Cxfe_Init (CM_VDSO_WhlSlipReRi3d_Cxfe_Init); unit Unit_None}, range phys -1..1.0000000000000009 Unit_None, raw 0..255, unit=Unit_None, transfer-property=TRIGGERED-WITHOUT-REPETITION  # Estimated wheel slip rear right. Estimation requires 3D IMU
          signal VDSO_BasTi200_NumClc_09_XIX_VDSO_09_XIX_HCP3_CANFD01: start 98, 4 bit, little-endian, data-type-policy=OVERRIDE, i-signal-type=PRIMITIVE, base-type=BT_VDSO_BasTi200_NumClc_09, compu {phys=raw for raw 0..15; unit Unit_None}, range phys 0..15 Unit_None, raw 0..15, unit=Unit_None, transfer-property=TRIGGERED-WITHOUT-REPETITION  # CalculationNumber of the VDSO 200 Runnable to enable PDU-TLT merge in receiver ECU
          signal VDSO_AgFrWhlStgAxlLWIOfsCmp_XIX_VDSO_09_XIX_HCP3_CANFD01: start 102, 16 bit, little-endian, data-type-policy=OVERRIDE, i-signal-type=PRIMITIVE, init-value=65534, base-type=BT_VDSO_AgFrWhlStgAxlLWIOfsCmp, invalid-value=Invalid_VDSO_AgFrWhlStgAxlLWIOfsCmp_XIX_VDSO_09_XIX_HCP3_CANFD01:65535, compu {phys=raw*3.195988376e-05-1.047197551 for raw 0..65532, 65535=Cxffff_Fehler (CM_VDSO_AgFrWhlStgAxlLWIOfsCmp_Cxffff_Fehler), 65534=Cxfffe_Init (CM_VDSO_AgFrWhlStgAxlLWIOfsCmp_Cxfffe_Init); unit Unit_Radia}, range phys -1.0471975511966..1.0471975511965936 Unit_Radia, raw 0..65535, unit=Unit_Radia, transfer-property=TRIGGERED-WITHOUT-REPETITION  # Steering angle of front axle including offset estimation. Calculation based on LWI-Signals
          signal VDSO_DKmtg_XIX_VDSO_09_XIX_HCP3_CANFD01: start 118, 32 bit, little-endian, data-type-policy=OVERRIDE, i-signal-type=PRIMITIVE, init-value=4294967294, base-type=BT_VDSO_DKmtg, invalid-value=Invalid_VDSO_DKmtg_XIX_VDSO_09_XIX_HCP3_CANFD01:4294967295, compu {phys=raw for raw 0..4294967293, 4294967295=Cxffffffff_Fehler (CM_VDSO_DKmtg_Cxffffffff_Fehler), 4294967294=Cxfffffffe_Init (CM_VDSO_DKmtg_Cxfffffffe_Init); unit Unit_Meter}, range phys 0..4294967293 Unit_Meter, raw 0..4294967295, unit=Unit_Meter, transfer-property=TRIGGERED-WITHOUT-REPETITION  # Vehicle lifetime traveled distance
          signal VDSO_DKmtg2Ord_XIX_VDSO_09_XIX_HCP3_CANFD01: start 150, 8 bit, little-endian, data-type-policy=OVERRIDE, i-signal-type=PRIMITIVE, init-value=254, base-type=BT_VDSO_DKmtg2Ord, invalid-value=Invalid_VDSO_DKmtg2Ord_XIX_VDSO_09_XIX_HCP3_CANFD01:255, compu {phys=raw for raw 0..253, 255=Cxff_Fehler (CM_VDSO_DKmtg2Ord_Cxff_Fehler), 254=Cxfe_Init (CM_VDSO_DKmtg2Ord_Cxfe_Init); unit Unit_Centimeter}, range phys 0..253 Unit_Centimeter, raw 0..255, unit=Unit_Centimeter, transfer-property=TRIGGERED-WITHOUT-REPETITION  # Distance traveled since the last full meter of VDSO_DKmtg.
      frame WFS_02_SOK_XIX_HCP3_CANFD01: id 0x1A555446, from HCP3_IONode, frame-length=32, can-addressing-mode=EXTENDED, can-frame-rx-behavior=CAN-FD, can-frame-tx-behavior=CAN-FD
        secured i pdu WFS_02_SOK_XIX_HCP3_CANFD01:
          length=32
          authentication-props=SecureCommunicationAuthenticationProps_XIX_32
          freshness-props=SecureCommunicationFreshnessProps
          payload=CHNL/PT_WFS_02
          secure-communication-props={auth-data-freshness-length=0, auth-data-freshness-start-position=0, auth-info-tx-length=32, authentication-build-attempts=1, authentication-retries=4, data-id=607, freshness-value-length=64, freshness-value-tx-length=0}
          use-as-cryptographic-i-pdu=false
      frame WLC1_03_XIX_HCP3_CANFD01: id 0x16A9555C, to HCP3_IONode, frame-length=12, can-addressing-mode=EXTENDED, can-frame-rx-behavior=CAN-FD, can-frame-tx-behavior=CAN-FD
        pdu WLC1_03_XIX_HCP3_CANFD01: length=12, minimum-delay=0.05, transmission-mode-true-timing={cyclic-timing={time-offset=0.0, time-period=1.0}, event-controlled-timing={number-of-repetitions=0, repetition-period=0.0}}, unused-bit-pattern=0
          signal WLC1_ChargingStatus_XIX_WLC1_03_XIX_HCP3_CANFD01: start 16, 8 bit, little-endian, data-type-policy=OVERRIDE, i-signal-type=PRIMITIVE, init-value=0, base-type=BT_WLC1_ChargingStatus, compu {3=Cx3_wlc_charging_active (CM_WLC1_ChargingStatus_Cx3_wlc_charging_active), 5=Cx5_foreign_object_detected (CM_WLC1_ChargingStatus_Cx5_foreign_object_detected), 0=Cx0_no_device_in_tray (CM_WLC1_ChargingStatus_Cx0_no_device_in_tray), 1=Cx1_no_wlc_device_in_tray (CM_WLC1_ChargingStatus_Cx1_no_wlc_device_in_tray), 4=Cx4_wlc_device_fully_charged (CM_WLC1_ChargingStatus_Cx4_wlc_device_fully_charged), 6=Cx6_nfc_card_and_wlc_device_detected (CM_WLC1_ChargingStatus_Cx6_nfc_card_and_wlc_device_detected), 2=Cx2_wlc_device_in_tray (CM_WLC1_ChargingStatus_Cx2_wlc_device_in_tray)}, range raw 0..6, transfer-property=TRIGGERED-ON-CHANGE-WITHOUT-REPETITION, to HCP3_IONode(timeout 5 s)  # This signal contains the charging status of WLC1.
          signal WLC1_ChargingEfficiency_XIX_WLC1_03_XIX_HCP3_CANFD01: start 24, 8 bit, little-endian, data-type-policy=OVERRIDE, i-signal-type=PRIMITIVE, init-value=0, base-type=BT_WLC1_ChargingEfficiency, compu {phys=raw for raw 0..100; unit Unit_PerCent}, range phys 0..100 Unit_PerCent, raw 0..100, unit=Unit_PerCent, transfer-property=TRIGGERED-ON-CHANGE-WITHOUT-REPETITION, to HCP3_IONode(timeout 5 s)  # This signal contains the charging efficiency in per cent of WLC1.
          signal WLC1_UsedChargingStandard_XIX_WLC1_03_XIX_HCP3_CANFD01: start 32, 8 bit, little-endian, data-type-policy=OVERRIDE, i-signal-type=PRIMITIVE, init-value=0, base-type=BT_WLC1_UsedChargingStandard, compu {2=Cx2_qi_fast_charge (CM_WLC1_UsedChargingStandard_Cx2_qi_fast_charge), 1=Cx1_qi (CM_WLC1_UsedChargingStandard_Cx1_qi), 3=Cx3_samsung_fast_charge (CM_WLC1_UsedChargingStandard_Cx3_samsung_fast_charge), 4=Cx4_apple_fast_charge (CM_WLC1_UsedChargingStandard_Cx4_apple_fast_charge), 5=Cx5_reduced_power_nfc_card_detected (CM_WLC1_UsedChargingStandard_Cx5_reduced_power_nfc_card_detected), 0=Cx0_charging_not_active (CM_WLC1_UsedChargingStandard_Cx0_charging_not_active)}, range raw 0..5, transfer-property=TRIGGERED-ON-CHANGE-WITHOUT-REPETITION, to HCP3_IONode(timeout 5 s)  # This signal contains the used charging standard of WLC1.
      frame WLC2_03_XIX_HCP3_CANFD01: id 0x16A9555D, to HCP3_IONode, frame-length=12, can-addressing-mode=EXTENDED, can-frame-rx-behavior=CAN-FD, can-frame-tx-behavior=CAN-FD
        pdu WLC2_03_XIX_HCP3_CANFD01: length=12, minimum-delay=0.05, transmission-mode-true-timing={cyclic-timing={time-offset=0.0, time-period=1.0}, event-controlled-timing={number-of-repetitions=0, repetition-period=0.0}}, unused-bit-pattern=0
          signal WLC2_ChargingStatus_XIX_WLC2_03_XIX_HCP3_CANFD01: start 16, 8 bit, little-endian, data-type-policy=OVERRIDE, i-signal-type=PRIMITIVE, init-value=0, base-type=BT_WLC2_ChargingStatus, compu {0=Cx0_no_device_in_tray (CM_WLC2_ChargingStatus_Cx0_no_device_in_tray), 4=Cx4_wlc_device_fully_charged (CM_WLC2_ChargingStatus_Cx4_wlc_device_fully_charged), 2=Cx2_wlc_device_in_tray (CM_WLC2_ChargingStatus_Cx2_wlc_device_in_tray), 5=Cx5_foreign_object_detected (CM_WLC2_ChargingStatus_Cx5_foreign_object_detected), 3=Cx3_wlc_charging_active (CM_WLC2_ChargingStatus_Cx3_wlc_charging_active), 1=Cx1_no_wlc_device_in_tray (CM_WLC2_ChargingStatus_Cx1_no_wlc_device_in_tray), 6=Cx6_nfc_card_and_wlc_device_detected (CM_WLC2_ChargingStatus_Cx6_nfc_card_and_wlc_device_detected)}, range raw 0..6, transfer-property=TRIGGERED-ON-CHANGE-WITHOUT-REPETITION, to HCP3_IONode(timeout 5 s)  # This signal contains the charging status of WLC2.
          signal WLC2_ChargingEfficiency_XIX_WLC2_03_XIX_HCP3_CANFD01: start 24, 8 bit, little-endian, data-type-policy=OVERRIDE, i-signal-type=PRIMITIVE, init-value=0, base-type=BT_WLC2_ChargingEfficiency, compu {phys=raw for raw 0..100; unit Unit_PerCent}, range phys 0..100 Unit_PerCent, raw 0..100, unit=Unit_PerCent, transfer-property=TRIGGERED-ON-CHANGE-WITHOUT-REPETITION, to HCP3_IONode(timeout 5 s)  # This signal contains the charging efficiency in per cent of WLC2.
          signal WLC2_UsedChargingStandard_XIX_WLC2_03_XIX_HCP3_CANFD01: start 32, 8 bit, little-endian, data-type-policy=OVERRIDE, i-signal-type=PRIMITIVE, init-value=0, base-type=BT_WLC2_UsedChargingStandard, compu {0=Cx0_charging_not_active (CM_WLC2_UsedChargingStandard_Cx0_charging_not_active), 2=Cx2_qi_fast_charge (CM_WLC2_UsedChargingStandard_Cx2_qi_fast_charge), 4=Cx4_apple_fast_charge (CM_WLC2_UsedChargingStandard_Cx4_apple_fast_charge), 3=Cx3_samsung_fast_charge (CM_WLC2_UsedChargingStandard_Cx3_samsung_fast_charge), 1=Cx1_qi (CM_WLC2_UsedChargingStandard_Cx1_qi), 5=Cx5_reduced_power_nfc_card_detected (CM_WLC2_UsedChargingStandard_Cx5_reduced_power_nfc_card_detected)}, range raw 0..5, transfer-property=TRIGGERED-ON-CHANGE-WITHOUT-REPETITION, to HCP3_IONode(timeout 5 s)  # This signal contains the used charging standard of WLC2.
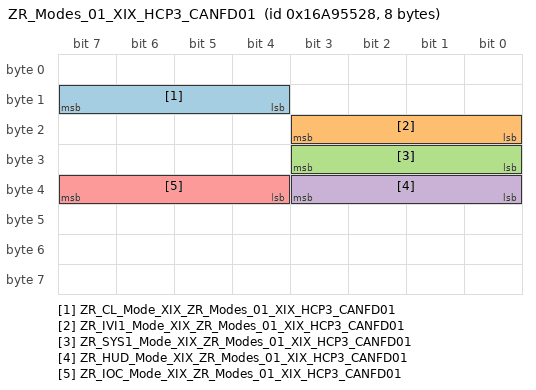
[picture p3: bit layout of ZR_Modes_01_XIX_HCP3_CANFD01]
      frame ZR_Modes_01_XIX_HCP3_CANFD01: id 0x16A95528, from HCP3_IONode, frame-length=8, can-addressing-mode=EXTENDED, can-frame-rx-behavior=CAN-FD, can-frame-tx-behavior=CAN-FD
        pdu ZR_Modes_01_XIX_HCP3_CANFD01: length=8, minimum-delay=0.04, transmission-mode-true-timing={cyclic-timing={time-offset=0.0, time-period=1.0}, event-controlled-timing={number-of-repetitions=0, repetition-period=0.0}}, unused-bit-pattern=0
          signal ZR_CL_Mode_XIX_ZR_Modes_01_XIX_HCP3_CANFD01: start 12, 4 bit, little-endian, data-type-policy=OVERRIDE, i-signal-type=PRIMITIVE, init-value=0, base-type=BT_ZR_CL_Mode, compu {0=Cx0_Undefined (CM_ZR_CL_Mode_Cx0_Undefined), 5=Cx5_Standby (CM_ZR_CL_Mode_Cx5_Standby), 6=Cx6_On (CM_ZR_CL_Mode_Cx6_On), 4=Cx4_Powersave (CM_ZR_CL_Mode_Cx4_Powersave), 2=Cx2_Sleep (CM_ZR_CL_Mode_Cx2_Sleep), 3=Cx3_Restricted (CM_ZR_CL_Mode_Cx3_Restricted), 1=Cx1_Off (CM_ZR_CL_Mode_Cx1_Off)}, range raw 0..6, transfer-property=TRIGGERED-ON-CHANGE-WITHOUT-REPETITION  # This signal contains MMI State of ZR_CL
          signal ZR_IVI1_Mode_XIX_ZR_Modes_01_XIX_HCP3_CANFD01: start 16, 4 bit, little-endian, data-type-policy=OVERRIDE, i-signal-type=PRIMITIVE, init-value=0, base-type=BT_ZR_IVI1_Mode, compu {0=Cx0_Undefined (CM_ZR_IVI1_Mode_Cx0_Undefined), 5=Cx5_Standby (CM_ZR_IVI1_Mode_Cx5_Standby), 1=Cx1_Off (CM_ZR_IVI1_Mode_Cx1_Off), 3=Cx3_Restricted (CM_ZR_IVI1_Mode_Cx3_Restricted), 6=Cx6_On (CM_ZR_IVI1_Mode_Cx6_On), 4=Cx4_Powersave (CM_ZR_IVI1_Mode_Cx4_Powersave), 2=Cx2_Sleep (CM_ZR_IVI1_Mode_Cx2_Sleep)}, range raw 0..6, transfer-property=TRIGGERED-ON-CHANGE-WITHOUT-REPETITION  # This signal contains MMI State of ZR_IVI1
          signal ZR_SYS1_Mode_XIX_ZR_Modes_01_XIX_HCP3_CANFD01: start 24, 4 bit, little-endian, data-type-policy=OVERRIDE, i-signal-type=PRIMITIVE, init-value=0, base-type=BT_ZR_SYS1_Mode, compu {0=Cx0_Undefined (CM_ZR_SYS1_Mode_Cx0_Undefined), 2=Cx2_Sleep (CM_ZR_SYS1_Mode_Cx2_Sleep), 4=Cx4_Powersave (CM_ZR_SYS1_Mode_Cx4_Powersave), 3=Cx3_Restricted (CM_ZR_SYS1_Mode_Cx3_Restricted), 6=Cx6_On (CM_ZR_SYS1_Mode_Cx6_On), 1=Cx1_Off (CM_ZR_SYS1_Mode_Cx1_Off), 5=Cx5_Standby (CM_ZR_SYS1_Mode_Cx5_Standby)}, range raw 0..6, transfer-property=TRIGGERED-ON-CHANGE-WITHOUT-REPETITION  # This signal contains MMI State of ZR_SYS1
          signal ZR_HUD_Mode_XIX_ZR_Modes_01_XIX_HCP3_CANFD01: start 32, 4 bit, little-endian, data-type-policy=OVERRIDE, i-signal-type=PRIMITIVE, init-value=0, base-type=BT_ZR_HUD_Mode, compu {0=Cx0_Undefined (CM_ZR_HUD_Mode_Cx0_Undefined), 1=Cx1_Off (CM_ZR_HUD_Mode_Cx1_Off), 6=Cx6_On (CM_ZR_HUD_Mode_Cx6_On), 2=Cx2_Sleep (CM_ZR_HUD_Mode_Cx2_Sleep), 5=Cx5_Standby (CM_ZR_HUD_Mode_Cx5_Standby), 4=Cx4_Powersave (CM_ZR_HUD_Mode_Cx4_Powersave), 3=Cx3_Restricted (CM_ZR_HUD_Mode_Cx3_Restricted)}, range raw 0..6, transfer-property=TRIGGERED-ON-CHANGE-WITHOUT-REPETITION  # This signal contains MMI State of ZR_HUD
          signal ZR_IOC_Mode_XIX_ZR_Modes_01_XIX_HCP3_CANFD01: start 36, 4 bit, little-endian, data-type-policy=OVERRIDE, i-signal-type=PRIMITIVE, init-value=0, base-type=BT_ZR_IOC_Mode, compu {6=Cx6_On (CM_ZR_IOC_Mode_Cx6_On), 1=Cx1_Off (CM_ZR_IOC_Mode_Cx1_Off), 0=Cx0_Undefined (CM_ZR_IOC_Mode_Cx0_Undefined), 5=Cx5_Standby (CM_ZR_IOC_Mode_Cx5_Standby), 4=Cx4_Powersave (CM_ZR_IOC_Mode_Cx4_Powersave), 3=Cx3_Restricted (CM_ZR_IOC_Mode_Cx3_Restricted), 2=Cx2_Sleep (CM_ZR_IOC_Mode_Cx2_Sleep)}, range raw 0..6, transfer-property=TRIGGERED-ON-CHANGE-WITHOUT-REPETITION  # This signal contains MMI State of ZR_IOC
      frame ZR_VA_Challenge_CID_XIX_HCP3_CANFD01: id 0x16A95560, from HCP3_IONode, frame-length=64, can-addressing-mode=EXTENDED, can-frame-rx-behavior=CAN-FD, can-frame-tx-behavior=CAN-FD
        pdu ZR_VA_Challenge_CID_XIX_HCP3_CANFD01: length=64, minimum-delay=0.1, transmission-mode-true-timing={cyclic-timing={time-offset=0.0, time-period=1.0}, event-controlled-timing={number-of-repetitions=0, repetition-period=0.0}}, unused-bit-pattern=0
          signal ZR_VA_Challenge_CID_XIX_ZR_VA_Challenge_CID_XIX_HCP3_CANFD01: start 0, 512 bit, opaque, data-type-policy=OVERRIDE, i-signal-type=ARRAY, init-value=64 x 0, base-type=BT_ZR_VA_Challenge_CID, implementation-data-type=ZR_VA_Challenge_CID, transfer-property=TRIGGERED-ON-CHANGE-WITHOUT-REPETITION  # Video-authentication challenge for CID
      frame ZR_VA_Challenge_PID_XIX_HCP3_CANFD01: id 0x16A95562, from HCP3_IONode, frame-length=64, can-addressing-mode=EXTENDED, can-frame-rx-behavior=CAN-FD, can-frame-tx-behavior=CAN-FD
        pdu ZR_VA_Challenge_PID_XIX_HCP3_CANFD01: length=64, minimum-delay=0.1, transmission-mode-true-timing={cyclic-timing={time-offset=0.0, time-period=1.0}, event-controlled-timing={number-of-repetitions=0, repetition-period=0.0}}, unused-bit-pattern=0
          signal ZR_VA_Challenge_PID_XIX_ZR_VA_Challenge_PID_XIX_HCP3_CANFD01: start 0, 512 bit, opaque, data-type-policy=OVERRIDE, i-signal-type=ARRAY, init-value=64 x 0, base-type=BT_ZR_VA_Challenge_PID, implementation-data-type=ZR_VA_Challenge_PID, transfer-property=TRIGGERED-ON-CHANGE-WITHOUT-REPETITION  # Video-authentication challenge for PID
      frame ZR_VA_Communication_Init_Ack_CID_XIX_HCP3_CANFD01: id 0x16A95586, from HCP3_IONode, frame-length=20, can-addressing-mode=EXTENDED, can-frame-rx-behavior=CAN-FD, can-frame-tx-behavior=CAN-FD
        pdu ZR_VA_Communication_Init_Ack_CID_XIX_HCP3_CANFD01: length=20, minimum-delay=0.1, transmission-mode-true-timing={cyclic-timing={time-offset=0.0, time-period=1.0}, event-controlled-timing={number-of-repetitions=0, repetition-period=0.0}}, unused-bit-pattern=0
          signal ZR_VA_Communication_Init_Ack_CID_XIX_ZR_VA_Communication_Init_Ack_CID_XIX_HCP3_CANFD01: start 0, 136 bit, opaque, data-type-policy=OVERRIDE, i-signal-type=ARRAY, init-value=17 x 0, base-type=BT_ZR_VA_Communication_Init_Ack_CID, implementation-data-type=ZR_VA_Communication_Init_Ack_CID, transfer-property=TRIGGERED-ON-CHANGE-WITHOUT-REPETITION  # This data channel is used for display video authentication of CID.
      frame ZR_VA_Communication_Init_Ack_PID_XIX_HCP3_CANFD01: id 0x16A95587, from HCP3_IONode, frame-length=20, can-addressing-mode=EXTENDED, can-frame-rx-behavior=CAN-FD, can-frame-tx-behavior=CAN-FD
        pdu ZR_VA_Communication_Init_Ack_PID_XIX_HCP3_CANFD01: length=20, minimum-delay=0.1, transmission-mode-true-timing={cyclic-timing={time-offset=0.0, time-period=1.0}, event-controlled-timing={number-of-repetitions=0, repetition-period=0.0}}, unused-bit-pattern=0
          signal ZR_VA_Communication_Init_Ack_PID_XIX_ZR_VA_Communication_Init_Ack_PID_XIX_HCP3_CANFD01: start 0, 136 bit, opaque, data-type-policy=OVERRIDE, i-signal-type=ARRAY, init-value=17 x 0, base-type=BT_ZR_VA_Communication_Init_Ack_PID, implementation-data-type=ZR_VA_Communication_Init_Ack_PID, transfer-property=TRIGGERED-ON-CHANGE-WITHOUT-REPETITION  # This data channel is used for display video authentication of PID.
      frame ZR_VA_Communication_Init_CID_XIX_HCP3_CANFD01: id 0x16A95563, from HCP3_IONode, frame-length=20, can-addressing-mode=EXTENDED, can-frame-rx-behavior=CAN-FD, can-frame-tx-behavior=CAN-FD
        pdu ZR_VA_Communication_Init_CID_XIX_HCP3_CANFD01: length=20, minimum-delay=0.1, transmission-mode-true-timing={cyclic-timing={time-offset=0.0, time-period=1.0}, event-controlled-timing={number-of-repetitions=0, repetition-period=0.0}}, unused-bit-pattern=0
          signal ZR_VA_Communication_Init_CID_XIX_ZR_VA_Communication_Init_CID_XIX_HCP3_CANFD01: start 0, 136 bit, opaque, data-type-policy=OVERRIDE, i-signal-type=ARRAY, init-value=17 x 0, base-type=BT_ZR_VA_Communication_Init_CID, implementation-data-type=ZR_VA_Communication_Init_CID, transfer-property=TRIGGERED-ON-CHANGE-WITHOUT-REPETITION  # Init communication of video-authentication from CID
      frame ZR_VA_Communication_Init_PID_XIX_HCP3_CANFD01: id 0x16A95565, from HCP3_IONode, frame-length=20, can-addressing-mode=EXTENDED, can-frame-rx-behavior=CAN-FD, can-frame-tx-behavior=CAN-FD
        pdu ZR_VA_Communication_Init_PID_XIX_HCP3_CANFD01: length=20, minimum-delay=0.1, transmission-mode-true-timing={cyclic-timing={time-offset=0.0, time-period=1.0}, event-controlled-timing={number-of-repetitions=0, repetition-period=0.0}}, unused-bit-pattern=0
          signal ZR_VA_Communication_Init_PID_XIX_ZR_VA_Communication_Init_PID_XIX_HCP3_CANFD01: start 0, 136 bit, opaque, data-type-policy=OVERRIDE, i-signal-type=ARRAY, init-value=17 x 0, base-type=BT_ZR_VA_Communication_Init_PID, implementation-data-type=ZR_VA_Communication_Init_PID, transfer-property=TRIGGERED-ON-CHANGE-WITHOUT-REPETITION  # Init communication of video-authentication from PID
      pdu triggering PT_WFS_02: pdu=WFS_02_XIX_HCP3_CANFD01, from HCP3_IONode
      pdu triggering PT_HCP3_CANFD01_XIX_TPCHType_CANFD_ARC_Master_XIX_0x1C403B1B_XIX_0x1C423B1B_XIX_Physical: pdu=CDD_HCP3_CANFD01_XIX_TPCHType_CANFD_ARC_Master_XIX_0x1C403B1B_XIX_0x1C423B1B_XIX_Physical, from HCP3_IONode
      pdu triggering PT_HCP3_CANFD01_XIX_TPCHType_CANFD_ARC_Master_XIX_0x1C423B1B_XIX_0x1C403B1B_XIX_Physical: pdu=CDD_HCP3_CANFD01_XIX_TPCHType_CANFD_ARC_Master_XIX_0x1C423B1B_XIX_0x1C403B1B_XIX_Physical, to HCP3_IONode
      pdu triggering PT_HCP3_CANFD01_XIX_TPCHType_CANFD_HID_Slave_XIX_0x1CD02268_XIX_0x1CD22268_XIX_Physical: pdu=CDD_HCP3_CANFD01_XIX_TPCHType_CANFD_HID_Slave_XIX_0x1CD02268_XIX_0x1CD22268_XIX_Physical, to HCP3_IONode
      pdu triggering PT_HCP3_CANFD01_XIX_TPCHType_CANFD_HID_Slave_XIX_0x1CD22268_XIX_0x1CD02268_XIX_Physical: pdu=CDD_HCP3_CANFD01_XIX_TPCHType_CANFD_HID_Slave_XIX_0x1CD22268_XIX_0x1CD02268_XIX_Physical, from HCP3_IONode
      pdu triggering PT_HCP3_CANFD01_XIX_TPCHType_CANFD_HID_Slave_XIX_0x1CD0226B_XIX_0x1CD2226B_XIX_Physical: pdu=CDD_HCP3_CANFD01_XIX_TPCHType_CANFD_HID_Slave_XIX_0x1CD0226B_XIX_0x1CD2226B_XIX_Physical, to HCP3_IONode
      pdu triggering PT_HCP3_CANFD01_XIX_TPCHType_CANFD_HID_Slave_XIX_0x1CD2226B_XIX_0x1CD0226B_XIX_Physical: pdu=CDD_HCP3_CANFD01_XIX_TPCHType_CANFD_HID_Slave_XIX_0x1CD2226B_XIX_0x1CD0226B_XIX_Physical, from HCP3_IONode
      pdu triggering PT_HCP3_CANFD01_XIX_TPCHType_CANFD_HID_Slave_XIX_0x1CD0226E_XIX_0x1CD2226E_XIX_Physical: pdu=CDD_HCP3_CANFD01_XIX_TPCHType_CANFD_HID_Slave_XIX_0x1CD0226E_XIX_0x1CD2226E_XIX_Physical, to HCP3_IONode
      pdu triggering PT_HCP3_CANFD01_XIX_TPCHType_CANFD_HID_Slave_XIX_0x1CD2226E_XIX_0x1CD0226E_XIX_Physical: pdu=CDD_HCP3_CANFD01_XIX_TPCHType_CANFD_HID_Slave_XIX_0x1CD2226E_XIX_0x1CD0226E_XIX_Physical, from HCP3_IONode
      pdu triggering PT_HCP3_CANFD01_XIX_TPCHType_CANFD_HID_Master_XIX_0x1C446822_XIX_0x1C466822_XIX_Physical: pdu=CDD_HCP3_CANFD01_XIX_TPCHType_CANFD_HID_Master_XIX_0x1C446822_XIX_0x1C466822_XIX_Physical, from HCP3_IONode
      pdu triggering PT_HCP3_CANFD01_XIX_TPCHType_CANFD_HID_Master_XIX_0x1C466822_XIX_0x1C446822_XIX_Physical: pdu=CDD_HCP3_CANFD01_XIX_TPCHType_CANFD_HID_Master_XIX_0x1C466822_XIX_0x1C446822_XIX_Physical, to HCP3_IONode
      pdu triggering PT_HCP3_CANFD01_XIX_TPCHType_CANFD_HID_Master_XIX_0x1C446723_XIX_0x1C466723_XIX_Physical: pdu=CDD_HCP3_CANFD01_XIX_TPCHType_CANFD_HID_Master_XIX_0x1C446723_XIX_0x1C466723_XIX_Physical, from HCP3_IONode
      pdu triggering PT_HCP3_CANFD01_XIX_TPCHType_CANFD_HID_Master_XIX_0x1C466723_XIX_0x1C446723_XIX_Physical: pdu=CDD_HCP3_CANFD01_XIX_TPCHType_CANFD_HID_Master_XIX_0x1C466723_XIX_0x1C446723_XIX_Physical, to HCP3_IONode
      pdu triggering PT_HCP3_CANFD01_XIX_TPCHType_CANFD_HID_Master_XIX_0x1C446B22_XIX_0x1C466B22_XIX_Physical: pdu=CDD_HCP3_CANFD01_XIX_TPCHType_CANFD_HID_Master_XIX_0x1C446B22_XIX_0x1C466B22_XIX_Physical, from HCP3_IONode
      pdu triggering PT_HCP3_CANFD01_XIX_TPCHType_CANFD_HID_Master_XIX_0x1C466B22_XIX_0x1C446B22_XIX_Physical: pdu=CDD_HCP3_CANFD01_XIX_TPCHType_CANFD_HID_Master_XIX_0x1C466B22_XIX_0x1C446B22_XIX_Physical, to HCP3_IONode
      pdu triggering PT_HCP3_CANFD01_XIX_TPCHType_CANFD_HID_Master_XIX_0x1C446A23_XIX_0x1C466A23_XIX_Physical: pdu=CDD_HCP3_CANFD01_XIX_TPCHType_CANFD_HID_Master_XIX_0x1C446A23_XIX_0x1C466A23_XIX_Physical, from HCP3_IONode
      pdu triggering PT_HCP3_CANFD01_XIX_TPCHType_CANFD_HID_Master_XIX_0x1C466A23_XIX_0x1C446A23_XIX_Physical: pdu=CDD_HCP3_CANFD01_XIX_TPCHType_CANFD_HID_Master_XIX_0x1C466A23_XIX_0x1C446A23_XIX_Physical, to HCP3_IONode
      pdu triggering PT_HCP3_CANFD01_XIX_TPCHType_CANFD_HID_Slave_XIX_0x1D001B73_XIX_0x1D021B73_XIX_Physical: pdu=CDD_HCP3_CANFD01_XIX_TPCHType_CANFD_HID_Slave_XIX_0x1D001B73_XIX_0x1D021B73_XIX_Physical, to HCP3_IONode
      pdu triggering PT_HCP3_CANFD01_XIX_TPCHType_CANFD_HID_Slave_XIX_0x1D021B73_XIX_0x1D001B73_XIX_Physical: pdu=CDD_HCP3_CANFD01_XIX_TPCHType_CANFD_HID_Slave_XIX_0x1D021B73_XIX_0x1D001B73_XIX_Physical, from HCP3_IONode
      pdu triggering PT_HCP3_CANFD01_XIX_TPCHType_CANFD_HID_Master_XIX_0x1D00731B_XIX_0x1D02731B_XIX_Physical: pdu=CDD_HCP3_CANFD01_XIX_TPCHType_CANFD_HID_Master_XIX_0x1D00731B_XIX_0x1D02731B_XIX_Physical, from HCP3_IONode
      pdu triggering PT_HCP3_CANFD01_XIX_TPCHType_CANFD_HID_Master_XIX_0x1D02731B_XIX_0x1D00731B_XIX_Physical: pdu=CDD_HCP3_CANFD01_XIX_TPCHType_CANFD_HID_Master_XIX_0x1D02731B_XIX_0x1D00731B_XIX_Physical, to HCP3_IONode
      pdu triggering PT_HCP3_CANFD01_XIX_TPCHType_CANFD_HID_Master_XIX_0x1C446E22_XIX_0x1C466E22_XIX_Physical: pdu=CDD_HCP3_CANFD01_XIX_TPCHType_CANFD_HID_Master_XIX_0x1C446E22_XIX_0x1C466E22_XIX_Physical, from HCP3_IONode
      pdu triggering PT_HCP3_CANFD01_XIX_TPCHType_CANFD_HID_Master_XIX_0x1C466E22_XIX_0x1C446E22_XIX_Physical: pdu=CDD_HCP3_CANFD01_XIX_TPCHType_CANFD_HID_Master_XIX_0x1C466E22_XIX_0x1C446E22_XIX_Physical, to HCP3_IONode
      pdu triggering PT_HCP3_CANFD01_XIX_TPCHType_CANFD_HID_Master_XIX_0x1C446C24_XIX_0x1C466C24_XIX_Physical: pdu=CDD_HCP3_CANFD01_XIX_TPCHType_CANFD_HID_Master_XIX_0x1C446C24_XIX_0x1C466C24_XIX_Physical, from HCP3_IONode
      pdu triggering PT_HCP3_CANFD01_XIX_TPCHType_CANFD_HID_Master_XIX_0x1C466C24_XIX_0x1C446C24_XIX_Physical: pdu=CDD_HCP3_CANFD01_XIX_TPCHType_CANFD_HID_Master_XIX_0x1C466C24_XIX_0x1C446C24_XIX_Physical, to HCP3_IONode
      pdu triggering PT_HCP3_CANFD01_XIX_TPCHType_CANFD_HID_Master_XIX_0x1C446D23_XIX_0x1C466D23_XIX_Physical: pdu=CDD_HCP3_CANFD01_XIX_TPCHType_CANFD_HID_Master_XIX_0x1C446D23_XIX_0x1C466D23_XIX_Physical, from HCP3_IONode
      pdu triggering PT_HCP3_CANFD01_XIX_TPCHType_CANFD_HID_Master_XIX_0x1C466D23_XIX_0x1C446D23_XIX_Physical: pdu=CDD_HCP3_CANFD01_XIX_TPCHType_CANFD_HID_Master_XIX_0x1C466D23_XIX_0x1C446D23_XIX_Physical, to HCP3_IONode
      pdu triggering PT_HCP3_CANFD01_XIX_TPCHType_CANFD_HID_Slave_XIX_0x1CD0246C_XIX_0x1CD2246C_XIX_Physical: pdu=CDD_HCP3_CANFD01_XIX_TPCHType_CANFD_HID_Slave_XIX_0x1CD0246C_XIX_0x1CD2246C_XIX_Physical, to HCP3_IONode
      pdu triggering PT_HCP3_CANFD01_XIX_TPCHType_CANFD_HID_Slave_XIX_0x1CD2246C_XIX_0x1CD0246C_XIX_Physical: pdu=CDD_HCP3_CANFD01_XIX_TPCHType_CANFD_HID_Slave_XIX_0x1CD2246C_XIX_0x1CD0246C_XIX_Physical, from HCP3_IONode
      pdu triggering PT_HCP3_CANFD01_XIX_TPCHType_CANFD_HID_Slave_XIX_0x1CD02367_XIX_0x1CD22367_XIX_Physical: pdu=CDD_HCP3_CANFD01_XIX_TPCHType_CANFD_HID_Slave_XIX_0x1CD02367_XIX_0x1CD22367_XIX_Physical, to HCP3_IONode
      pdu triggering PT_HCP3_CANFD01_XIX_TPCHType_CANFD_HID_Slave_XIX_0x1CD22367_XIX_0x1CD02367_XIX_Physical: pdu=CDD_HCP3_CANFD01_XIX_TPCHType_CANFD_HID_Slave_XIX_0x1CD22367_XIX_0x1CD02367_XIX_Physical, from HCP3_IONode
      pdu triggering PT_HCP3_CANFD01_XIX_TPCHType_CANFD_HID_Slave_XIX_0x1CD0236A_XIX_0x1CD2236A_XIX_Physical: pdu=CDD_HCP3_CANFD01_XIX_TPCHType_CANFD_HID_Slave_XIX_0x1CD0236A_XIX_0x1CD2236A_XIX_Physical, to HCP3_IONode
      pdu triggering PT_HCP3_CANFD01_XIX_TPCHType_CANFD_HID_Slave_XIX_0x1CD2236A_XIX_0x1CD0236A_XIX_Physical: pdu=CDD_HCP3_CANFD01_XIX_TPCHType_CANFD_HID_Slave_XIX_0x1CD2236A_XIX_0x1CD0236A_XIX_Physical, from HCP3_IONode
      pdu triggering PT_HCP3_CANFD01_XIX_TPCHType_CANFD_HID_Slave_XIX_0x1CD0236D_XIX_0x1CD2236D_XIX_Physical: pdu=CDD_HCP3_CANFD01_XIX_TPCHType_CANFD_HID_Slave_XIX_0x1CD0236D_XIX_0x1CD2236D_XIX_Physical, to HCP3_IONode
      pdu triggering PT_HCP3_CANFD01_XIX_TPCHType_CANFD_HID_Slave_XIX_0x1CD2236D_XIX_0x1CD0236D_XIX_Physical: pdu=CDD_HCP3_CANFD01_XIX_TPCHType_CANFD_HID_Slave_XIX_0x1CD2236D_XIX_0x1CD0236D_XIX_Physical, from HCP3_IONode
      pdu triggering PT_HCP3_CANFD01_XIX_TPCHType_CANFD_ARC_Slave_XIX_0x1CC01B3B_XIX_0x1CC21B3B_XIX_Physical: pdu=CDD_HCP3_CANFD01_XIX_TPCHType_CANFD_ARC_Slave_XIX_0x1CC01B3B_XIX_0x1CC21B3B_XIX_Physical, to HCP3_IONode
      pdu triggering PT_HCP3_CANFD01_XIX_TPCHType_CANFD_ARC_Slave_XIX_0x1CC21B3B_XIX_0x1CC01B3B_XIX_Physical: pdu=CDD_HCP3_CANFD01_XIX_TPCHType_CANFD_ARC_Slave_XIX_0x1CC21B3B_XIX_0x1CC01B3B_XIX_Physical, from HCP3_IONode
      pdu triggering PT_HCP3_CANFD01_XIX_TPCHType_CANFD_Flash_DIA_XIX_0x1C401693_XIX_0x1C421693_XIX_Physical: pdu=DCM_HCP3_CANFD01_XIX_TPCHType_CANFD_Flash_DIA_XIX_0x1C401693_XIX_0x1C421693_XIX_Physical, from HCP3_IONode
      pdu triggering PT_HCP3_CANFD01_XIX_TPCHType_CANFD_Flash_DIA_XIX_0x1C421693_XIX_0x1C401693_XIX_Physical: pdu=DCM_HCP3_CANFD01_XIX_TPCHType_CANFD_Flash_DIA_XIX_0x1C421693_XIX_0x1C401693_XIX_Physical, to HCP3_IONode
      pdu triggering PT_HCP3_CANFD01_XIX_TPCHType_CANFD_Diag_XIX_0x1C400693_XIX_0x1C420693_XIX_Physical: pdu=DCM_HCP3_CANFD01_XIX_TPCHType_CANFD_Diag_XIX_0x1C400693_XIX_0x1C420693_XIX_Physical, from HCP3_IONode
      pdu triggering PT_HCP3_CANFD01_XIX_TPCHType_CANFD_Diag_XIX_0x1C420693_XIX_0x1C400693_XIX_Physical: pdu=DCM_HCP3_CANFD01_XIX_TPCHType_CANFD_Diag_XIX_0x1C420693_XIX_0x1C400693_XIX_Physical, to HCP3_IONode
      pdu triggering PT_HCP3_CANFD01_XIX_TPCHType_CANFD_ISO_Diagnose_XIX_0x1C440024_XIX_0x1C460024_XIX_Physical: pdu=DCM_HCP3_CANFD01_XIX_TPCHType_CANFD_ISO_Diagnose_XIX_0x1C440024_XIX_0x1C460024_XIX_Physical, from HCP3_IONode
      pdu triggering PT_HCP3_CANFD01_XIX_TPCHType_CANFD_ISO_Diagnose_XIX_0x1C460024_XIX_0x1C440024_XIX_Physical: pdu=DCM_HCP3_CANFD01_XIX_TPCHType_CANFD_ISO_Diagnose_XIX_0x1C460024_XIX_0x1C440024_XIX_Physical, to HCP3_IONode
      pdu triggering PT_HCP3_CANFD01_XIX_TPCHType_CANFD_ISO_Diagnose_XIX_0x1C440022_XIX_0x1C460022_XIX_Physical: pdu=DCM_HCP3_CANFD01_XIX_TPCHType_CANFD_ISO_Diagnose_XIX_0x1C440022_XIX_0x1C460022_XIX_Physical, from HCP3_IONode
      pdu triggering PT_HCP3_CANFD01_XIX_TPCHType_CANFD_ISO_Diagnose_XIX_0x1C460022_XIX_0x1C440022_XIX_Physical: pdu=DCM_HCP3_CANFD01_XIX_TPCHType_CANFD_ISO_Diagnose_XIX_0x1C460022_XIX_0x1C440022_XIX_Physical, to HCP3_IONode
      pdu triggering PT_HCP3_CANFD01_XIX_TPCHType_CANFD_ISO_Diagnose_XIX_0x1C410000_XIX_Functional: pdu=DCM_HCP3_CANFD01_XIX_TPCHType_CANFD_ISO_Diagnose_XIX_0x1C410000_XIX_Functional, from HCP3_IONode
      pdu triggering PT_HCP3_CANFD01_XIX_TPCHType_CANFD_ISO_Diagnose_XIX_0x1C40001B_XIX_0x1C42001B_XIX_Physical: pdu=DCM_HCP3_CANFD01_XIX_TPCHType_CANFD_ISO_Diagnose_XIX_0x1C40001B_XIX_0x1C42001B_XIX_Physical, from HCP3_IONode
      pdu triggering PT_HCP3_CANFD01_XIX_TPCHType_CANFD_ISO_Diagnose_XIX_0x1C42001B_XIX_0x1C40001B_XIX_Physical: pdu=DCM_HCP3_CANFD01_XIX_TPCHType_CANFD_ISO_Diagnose_XIX_0x1C42001B_XIX_0x1C40001B_XIX_Physical, to HCP3_IONode
      pdu triggering PT_HCP3_CANFD01_XIX_TPCHType_CANFD_ISO_Diagnose_XIX_0x1C440023_XIX_0x1C460023_XIX_Physical: pdu=DCM_HCP3_CANFD01_XIX_TPCHType_CANFD_ISO_Diagnose_XIX_0x1C440023_XIX_0x1C460023_XIX_Physical, from HCP3_IONode
      pdu triggering PT_HCP3_CANFD01_XIX_TPCHType_CANFD_ISO_Diagnose_XIX_0x1C460023_XIX_0x1C440023_XIX_Physical: pdu=DCM_HCP3_CANFD01_XIX_TPCHType_CANFD_ISO_Diagnose_XIX_0x1C460023_XIX_0x1C440023_XIX_Physical, to HCP3_IONode
      pdu triggering PT_HCP3_CANFD01_XIX_TPCHType_CANFD_ISO_Diagnose_XIX_0x1C4000A5_XIX_0x1C4200A5_XIX_Physical: pdu=DCM_HCP3_CANFD01_XIX_TPCHType_CANFD_ISO_Diagnose_XIX_0x1C4000A5_XIX_0x1C4200A5_XIX_Physical, from HCP3_IONode
      pdu triggering PT_HCP3_CANFD01_XIX_TPCHType_CANFD_ISO_Diagnose_XIX_0x1C4200A5_XIX_0x1C4000A5_XIX_Physical: pdu=DCM_HCP3_CANFD01_XIX_TPCHType_CANFD_ISO_Diagnose_XIX_0x1C4200A5_XIX_0x1C4000A5_XIX_Physical, to HCP3_IONode
      pdu triggering PT_HCP3_CANFD01_XIX_TPCHType_CANFD_ISO_Diagnose_XIX_0x1C4000A6_XIX_0x1C4200A6_XIX_Physical: pdu=DCM_HCP3_CANFD01_XIX_TPCHType_CANFD_ISO_Diagnose_XIX_0x1C4000A6_XIX_0x1C4200A6_XIX_Physical, from HCP3_IONode
      pdu triggering PT_HCP3_CANFD01_XIX_TPCHType_CANFD_ISO_Diagnose_XIX_0x1C4200A6_XIX_0x1C4000A6_XIX_Physical: pdu=DCM_HCP3_CANFD01_XIX_TPCHType_CANFD_ISO_Diagnose_XIX_0x1C4200A6_XIX_0x1C4000A6_XIX_Physical, to HCP3_IONode
      pdu triggering PT_HCP3_CANFD01_XIX_TPCHType_CANFD_OBDC_Diagnose_XIX_0x1C410200_XIX_Functional: pdu=DCM_HCP3_CANFD01_XIX_TPCHType_CANFD_OBDC_Diagnose_XIX_0x1C410200_XIX_Functional, from HCP3_IONode
      pdu triggering PT_HCP3_CANFD01_XIX_TPCHType_CANFD_OBDC_Diagnose_XIX_0x1C440224_XIX_0x1C460224_XIX_Physical: pdu=DCM_HCP3_CANFD01_XIX_TPCHType_CANFD_OBDC_Diagnose_XIX_0x1C440224_XIX_0x1C460224_XIX_Physical, from HCP3_IONode
      pdu triggering PT_HCP3_CANFD01_XIX_TPCHType_CANFD_OBDC_Diagnose_XIX_0x1C460224_XIX_0x1C440224_XIX_Physical: pdu=DCM_HCP3_CANFD01_XIX_TPCHType_CANFD_OBDC_Diagnose_XIX_0x1C460224_XIX_0x1C440224_XIX_Physical, to HCP3_IONode
      pdu triggering PT_HCP3_CANFD01_XIX_TPCHType_CANFD_OBDC_Diagnose_XIX_0x1C440222_XIX_0x1C460222_XIX_Physical: pdu=DCM_HCP3_CANFD01_XIX_TPCHType_CANFD_OBDC_Diagnose_XIX_0x1C440222_XIX_0x1C460222_XIX_Physical, from HCP3_IONode
      pdu triggering PT_HCP3_CANFD01_XIX_TPCHType_CANFD_OBDC_Diagnose_XIX_0x1C460222_XIX_0x1C440222_XIX_Physical: pdu=DCM_HCP3_CANFD01_XIX_TPCHType_CANFD_OBDC_Diagnose_XIX_0x1C460222_XIX_0x1C440222_XIX_Physical, to HCP3_IONode
      pdu triggering PT_HCP3_CANFD01_XIX_TPCHType_CANFD_OBDC_Diagnose_XIX_0x1C40021B_XIX_0x1C42021B_XIX_Physical: pdu=DCM_HCP3_CANFD01_XIX_TPCHType_CANFD_OBDC_Diagnose_XIX_0x1C40021B_XIX_0x1C42021B_XIX_Physical, from HCP3_IONode
      pdu triggering PT_HCP3_CANFD01_XIX_TPCHType_CANFD_OBDC_Diagnose_XIX_0x1C42021B_XIX_0x1C40021B_XIX_Physical: pdu=DCM_HCP3_CANFD01_XIX_TPCHType_CANFD_OBDC_Diagnose_XIX_0x1C42021B_XIX_0x1C40021B_XIX_Physical, to HCP3_IONode
      pdu triggering PT_HCP3_CANFD01_XIX_TPCHType_CANFD_OBDC_SSN_Diagnose_XIX_0x1C407093_XIX_0x1C427093_XIX_Physical: pdu=DCM_HCP3_CANFD01_XIX_TPCHType_CANFD_OBDC_SSN_Diagnose_XIX_0x1C407093_XIX_0x1C427093_XIX_Physical, from HCP3_IONode
      pdu triggering PT_HCP3_CANFD01_XIX_TPCHType_CANFD_OBDC_SSN_Diagnose_XIX_0x1C427093_XIX_0x1C407093_XIX_Physical: pdu=DCM_HCP3_CANFD01_XIX_TPCHType_CANFD_OBDC_SSN_Diagnose_XIX_0x1C427093_XIX_0x1C407093_XIX_Physical, to HCP3_IONode
      pdu triggering PT_HCP3_CANFD01_XIX_TPCHType_CANFD_OBDC_Diagnose_XIX_0x1C440223_XIX_0x1C460223_XIX_Physical: pdu=DCM_HCP3_CANFD01_XIX_TPCHType_CANFD_OBDC_Diagnose_XIX_0x1C440223_XIX_0x1C460223_XIX_Physical, from HCP3_IONode
      pdu triggering PT_HCP3_CANFD01_XIX_TPCHType_CANFD_OBDC_Diagnose_XIX_0x1C460223_XIX_0x1C440223_XIX_Physical: pdu=DCM_HCP3_CANFD01_XIX_TPCHType_CANFD_OBDC_Diagnose_XIX_0x1C460223_XIX_0x1C440223_XIX_Physical, to HCP3_IONode
      pdu triggering PT_HCP3_CANFD01_XIX_TPCHType_CANFD_OBDC_Diagnose_XIX_0x1C4002A5_XIX_0x1C4202A5_XIX_Physical: pdu=DCM_HCP3_CANFD01_XIX_TPCHType_CANFD_OBDC_Diagnose_XIX_0x1C4002A5_XIX_0x1C4202A5_XIX_Physical, from HCP3_IONode
      pdu triggering PT_HCP3_CANFD01_XIX_TPCHType_CANFD_OBDC_Diagnose_XIX_0x1C4202A5_XIX_0x1C4002A5_XIX_Physical: pdu=DCM_HCP3_CANFD01_XIX_TPCHType_CANFD_OBDC_Diagnose_XIX_0x1C4202A5_XIX_0x1C4002A5_XIX_Physical, to HCP3_IONode
      pdu triggering PT_HCP3_CANFD01_XIX_TPCHType_CANFD_OBDC_Diagnose_XIX_0x1C4002A6_XIX_0x1C4202A6_XIX_Physical: pdu=DCM_HCP3_CANFD01_XIX_TPCHType_CANFD_OBDC_Diagnose_XIX_0x1C4002A6_XIX_0x1C4202A6_XIX_Physical, from HCP3_IONode
      pdu triggering PT_HCP3_CANFD01_XIX_TPCHType_CANFD_OBDC_Diagnose_XIX_0x1C4202A6_XIX_0x1C4002A6_XIX_Physical: pdu=DCM_HCP3_CANFD01_XIX_TPCHType_CANFD_OBDC_Diagnose_XIX_0x1C4202A6_XIX_0x1C4002A6_XIX_Physical, to HCP3_IONode
